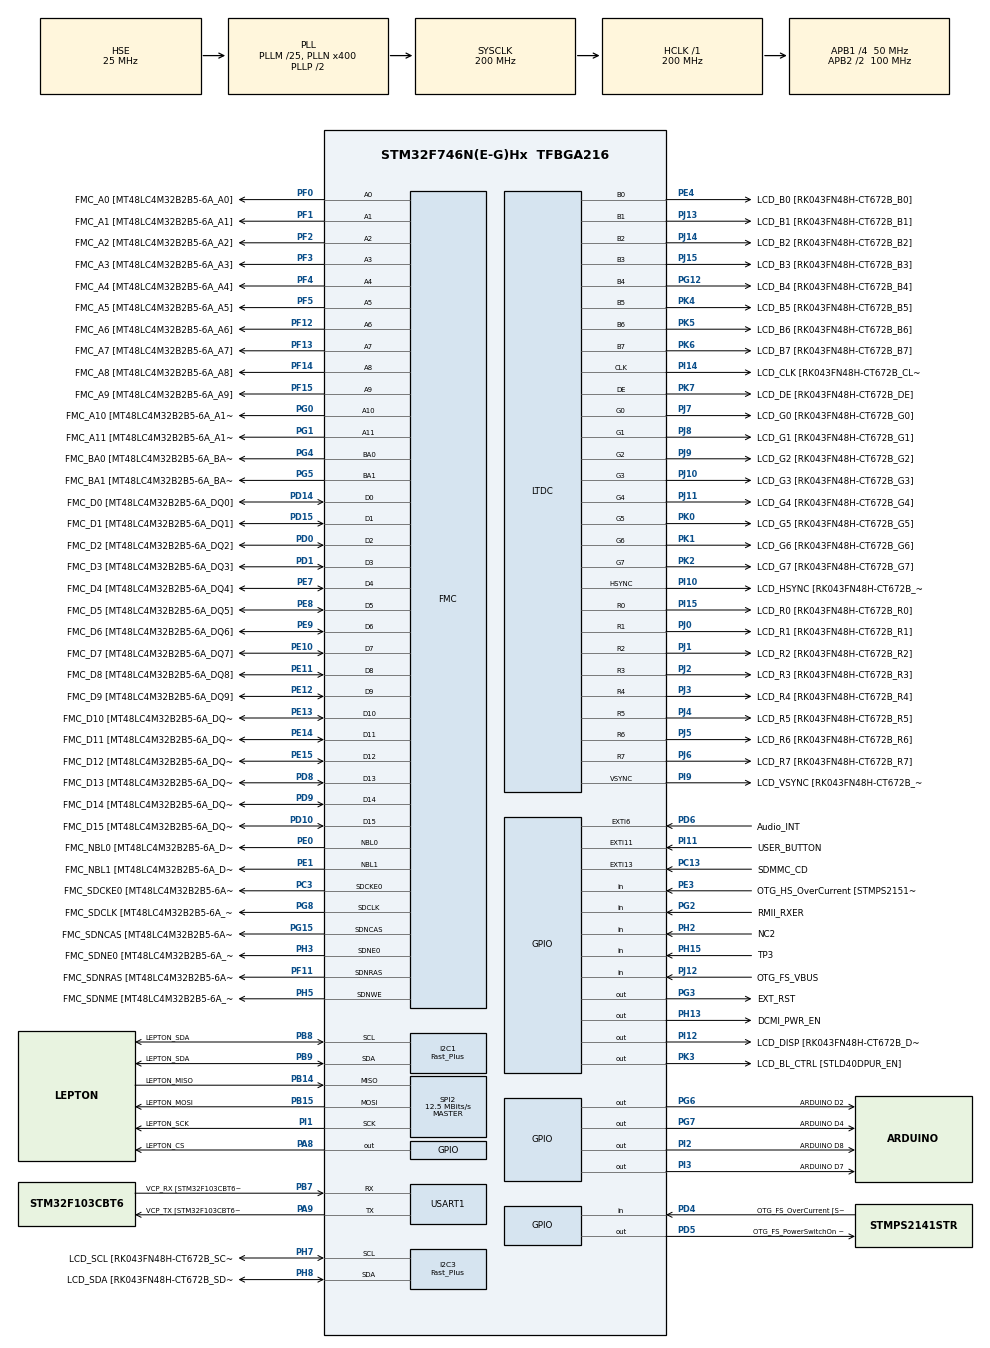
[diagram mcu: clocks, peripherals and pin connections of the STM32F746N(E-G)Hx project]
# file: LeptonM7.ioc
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CORTEX_M7.CPU_DCache=Enabled
CORTEX_M7.CPU_ICache=Enabled
CRC.InputDataFormat=CRC_INPUTDATA_FORMAT_HALFWORDS
DMA2D.AlphaModeForeground=DMA2D_NO_MODIF_ALPHA
DMA2D.InputAlphaForeground=0xFF
Dma.Request0=SPI2_RX
Dma.Request1=SPI2_TX
Dma.SPI2_RX.0.Channel=DMA_CHANNEL_0
Dma.SPI2_RX.0.Direction=DMA_PERIPH_TO_MEMORY
Dma.SPI2_RX.0.FIFOMode=DMA_FIFOMODE_ENABLE
Dma.SPI2_RX.0.FIFOThreshold=DMA_FIFO_THRESHOLD_FULL
Dma.SPI2_RX.0.Instance=DMA1_Stream3
Dma.SPI2_RX.0.MemBurst=DMA_MBURST_SINGLE
Dma.SPI2_RX.0.MemDataAlignment=DMA_MDATAALIGN_BYTE
Dma.SPI2_RX.0.MemInc=DMA_MINC_ENABLE
Dma.SPI2_RX.0.Mode=DMA_NORMAL
Dma.SPI2_RX.0.PeriphBurst=DMA_PBURST_SINGLE
Dma.SPI2_RX.0.PeriphDataAlignment=DMA_PDATAALIGN_BYTE
Dma.SPI2_RX.0.PeriphInc=DMA_PINC_DISABLE
Dma.SPI2_RX.0.Priority=DMA_PRIORITY_VERY_HIGH
Dma.SPI2_TX.1.Channel=DMA_CHANNEL_0
Dma.SPI2_TX.1.Direction=DMA_MEMORY_TO_PERIPH
Dma.SPI2_TX.1.FIFOMode=DMA_FIFOMODE_ENABLE
Dma.SPI2_TX.1.FIFOThreshold=DMA_FIFO_THRESHOLD_FULL
Dma.SPI2_TX.1.Instance=DMA1_Stream4
Dma.SPI2_TX.1.MemBurst=DMA_MBURST_SINGLE
Dma.SPI2_TX.1.MemDataAlignment=DMA_MDATAALIGN_BYTE
Dma.SPI2_TX.1.MemInc=DMA_MINC_ENABLE
Dma.SPI2_TX.1.Mode=DMA_NORMAL
Dma.SPI2_TX.1.PeriphBurst=DMA_PBURST_SINGLE
Dma.SPI2_TX.1.PeriphDataAlignment=DMA_PDATAALIGN_BYTE
Dma.SPI2_TX.1.PeriphInc=DMA_PINC_DISABLE
Dma.SPI2_TX.1.Priority=DMA_PRIORITY_LOW
FMC.CASLatency1=FMC_SDRAM_CAS_LATENCY_2
FMC.ExitSelfRefreshDelay1=6
FMC.LoadToActiveDelay1=2
FMC.RCDDelay1=2
FMC.RPDelay1=2
FMC.RPDelay2=2
FMC.ReadBurst1=FMC_SDRAM_RBURST_ENABLE
FMC.ReadBurst2=FMC_SDRAM_RBURST_ENABLE
FMC.RowBitsNumber1=FMC_SDRAM_ROW_BITS_NUM_12
FMC.RowCycleDelay1=6
FMC.RowCycleDelay2=6
FMC.SDClockPeriod1=FMC_SDRAM_CLOCK_PERIOD_2
FMC.SDClockPeriod2=FMC_SDRAM_CLOCK_PERIOD_2
FMC.SelfRefreshTime1=4
FMC.WriteRecoveryTime1=2
I2C1.I2C_Speed_Mode=I2C_Fast_Plus
I2C1.Speed=400
I2C1.Timing=0x00200A6D
I2C3.I2C_Speed_Mode=I2C_Fast_Plus
I2C3.Speed=400
I2C3.Timing=0x00200A6D
LTDC.ActiveH=272
LTDC.ActiveW=480
LTDC.Alpha_L0=255
LTDC.Alpha_L1=255
LTDC.BlendingFactor1_L0=LTDC_BLENDING_FACTOR1_PAxCA
LTDC.BlendingFactor1_L1=LTDC_BLENDING_FACTOR1_PAxCA
LTDC.BlendingFactor2_L0=LTDC_BLENDING_FACTOR2_PAxCA
LTDC.BlendingFactor2_L1=LTDC_BLENDING_FACTOR2_PAxCA
LTDC.FBStartAdress_L0=0xC0000000
LTDC.FBStartAdress_L1=0xC0100000
LTDC.HBP=13
LTDC.HFP=32
LTDC.HSync=41
LTDC.ImageHeight_L0=240
LTDC.ImageHeight_L1=272
LTDC.ImageWidth_L0=320
LTDC.ImageWidth_L1=480
LTDC.PCPolarity=LTDC_PCPOLARITY_IPC
LTDC.VBP=2
LTDC.VSync=10
LTDC.WindowX0_L0=80
LTDC.WindowX0_L1=0
LTDC.WindowX1_L0=399
LTDC.WindowX1_L1=479
LTDC.WindowY0_L0=16
LTDC.WindowY0_L1=0
LTDC.WindowY1_L0=255
LTDC.WindowY1_L1=271
Mcu.Family=STM32F7
Mcu.Name=STM32F746N(E-G)Hx
Mcu.Package=TFBGA216
NVIC.DMA1_Stream3_IRQn=true\:4\:0\:true
NVIC.DMA1_Stream4_IRQn=true\:3\:0\:true
NVIC.EXTI15_10_IRQn=true\:1\:0\:true
NVIC.PriorityGroup=NVIC_PRIORITYGROUP_4
NVIC.TIM2_IRQn=true\:2\:0\:true
PA0/WKUP.GPIO_Label=ARDUINO A0
PA0/WKUP.GPIO_Mode=GPIO_MODE_ANALOG
PA0/WKUP.GPIO_PuPd=GPIO_NOPULL
PA0/WKUP.Signal=ADCx_IN0
PA1.GPIO_Label=RMII_REF_CLK [LAN8742A-CZ-TR_REFCLK0]
PA1.GPIO_Mode=GPIO_MODE_AF_PP
PA1.GPIO_PuPd=GPIO_NOPULL
PA1.GPIO_Speed=GPIO_SPEED_HIGH
PA1.Signal=ETH_REF_CLK
PA10.GPIO_Label=OTG_FS_ID
PA10.GPIO_Mode=GPIO_MODE_AF_PP
PA10.GPIO_PuPd=GPIO_NOPULL
PA10.GPIO_Speed=GPIO_SPEED_HIGH
PA10.Signal=USB_OTG_FS_ID
PA11.GPIO_Label=OTG_FS_N
PA11.GPIO_Mode=GPIO_MODE_AF_PP
PA11.GPIO_PuPd=GPIO_NOPULL
PA11.GPIO_Speed=GPIO_SPEED_HIGH
PA11.Signal=USB_OTG_FS_DM
PA12.GPIO_Label=OTG_FS_P
PA12.GPIO_Mode=GPIO_MODE_AF_PP
PA12.GPIO_PuPd=GPIO_NOPULL
PA12.GPIO_Speed=GPIO_SPEED_HIGH
PA12.Signal=USB_OTG_FS_DP
PA13.GPIO_Label=SWDIO
PA13.Mode=Trace-Asynchronous_SW
PA13.Signal=SYS_JTMS-SWDIO
PA14.GPIO_Label=SWCLK
PA14.Mode=Trace-Asynchronous_SW
PA14.Signal=SYS_JTCK-SWCLK
PA15.GPIO_Label=ARDUINO PWM/D9
PA15.GPIO_ModeDefaultPP=GPIO_MODE_AF_PP
PA15.GPIO_PuPd=GPIO_NOPULL
PA15.GPIO_Speed=GPIO_SPEED_LOW
PA15.Signal=S_TIM2_CH1_ETR
PA2.GPIO_Label=RMII_MDIO [LAN8742A-CZ-TR_MDIO]
PA2.GPIO_Mode=GPIO_MODE_AF_PP
PA2.GPIO_PuPd=GPIO_NOPULL
PA2.GPIO_Speed=GPIO_SPEED_HIGH
PA2.Signal=ETH_MDIO
PA3.GPIO_Label=ULPI_D0 [USB3320C-EZK_D0]
PA3.GPIO_Mode=GPIO_MODE_AF_PP
PA3.GPIO_PuPd=GPIO_NOPULL
PA3.GPIO_Speed=GPIO_SPEED_HIGH
PA3.Signal=USB_OTG_HS_ULPI_D0
PA4.GPIO_Label=DCMI_HSYNC
PA4.GPIO_Mode=GPIO_MODE_AF_PP
PA4.GPIO_PuPd=GPIO_NOPULL
PA4.GPIO_Speed=GPIO_SPEED_LOW
PA4.Signal=DCMI_HSYNC
PA5.GPIO_Label=ULPI_CLK [USB3320C-EZK_CLKOUT]
PA5.GPIO_Mode=GPIO_MODE_AF_PP
PA5.GPIO_PuPd=GPIO_NOPULL
PA5.GPIO_Speed=GPIO_SPEED_HIGH
PA5.Signal=USB_OTG_HS_ULPI_CK
PA6.Signal=DCMI_PIXCLK
PA7.GPIO_Label=RMII_CRS_DV [LAN8742A-CZ-TR_CRS_DV]
PA7.GPIO_Mode=GPIO_MODE_AF_PP
PA7.GPIO_PuPd=GPIO_NOPULL
PA7.GPIO_Speed=GPIO_SPEED_HIGH
PA7.Signal=ETH_CRS_DV
PA8.GPIO_Label=LEPTON_CS
PA8.GPIO_ModeDefaultOutputPP=GPIO_MODE_OUTPUT_PP
PA8.GPIO_PuPd=GPIO_NOPULL
PA8.GPIO_Speed=GPIO_SPEED_MEDIUM
PA8.Signal=GPIO_Output
PA9.GPIO_Label=VCP_TX [STM32F103CBT6_PA3]
PA9.GPIO_Mode=GPIO_MODE_AF_PP
PA9.GPIO_PuPd=GPIO_NOPULL
PA9.GPIO_Speed=GPIO_SPEED_MEDIUM
PA9.Mode=Asynchronous
PA9.Signal=USART1_TX
PB0.GPIO_Label=ULPI_D1 [USB3320C-EZK_D1]
PB0.GPIO_Mode=GPIO_MODE_AF_PP
PB0.GPIO_PuPd=GPIO_NOPULL
PB0.GPIO_Speed=GPIO_SPEED_HIGH
PB0.Signal=USB_OTG_HS_ULPI_D1
PB1.GPIO_Label=ULPI_D2 [USB3320C-EZK_D2]
PB1.GPIO_Mode=GPIO_MODE_AF_PP
PB1.GPIO_PuPd=GPIO_NOPULL
PB1.GPIO_Speed=GPIO_SPEED_HIGH
PB1.Signal=USB_OTG_HS_ULPI_D2
PB10.GPIO_Label=ULPI_D3 [USB3320C-EZK_D3]
PB10.GPIO_Mode=GPIO_MODE_AF_PP
PB10.GPIO_PuPd=GPIO_NOPULL
PB10.GPIO_Speed=GPIO_SPEED_HIGH
PB10.Signal=USB_OTG_HS_ULPI_D3
PB11.GPIO_Label=ULPI_D4 [USB3320C-EZK_D4]
PB11.GPIO_Mode=GPIO_MODE_AF_PP
PB11.GPIO_PuPd=GPIO_NOPULL
PB11.GPIO_Speed=GPIO_SPEED_HIGH
PB11.Signal=USB_OTG_HS_ULPI_D4
PB12.GPIO_Label=ULPI_D5 [USB3320C-EZK_D5]
PB12.GPIO_Mode=GPIO_MODE_AF_PP
PB12.GPIO_PuPd=GPIO_NOPULL
PB12.GPIO_Speed=GPIO_SPEED_HIGH
PB12.Signal=USB_OTG_HS_ULPI_D5
PB13.GPIO_Label=ULPI_D6 [USB3320C-EZK_D6]
PB13.GPIO_Mode=GPIO_MODE_AF_PP
PB13.GPIO_PuPd=GPIO_NOPULL
PB13.GPIO_Speed=GPIO_SPEED_HIGH
PB13.Signal=USB_OTG_HS_ULPI_D6
PB14.GPIO_Label=LEPTON_MISO
PB14.GPIO_Mode=GPIO_MODE_AF_PP
PB14.GPIO_PuPd=GPIO_NOPULL
PB14.GPIO_Speed=GPIO_SPEED_FAST
PB14.Mode=Full_Duplex_Master
PB14.Signal=SPI2_MISO
PB15.GPIO_Label=LEPTON_MOSI
PB15.GPIO_Mode=GPIO_MODE_AF_PP
PB15.GPIO_PuPd=GPIO_NOPULL
PB15.GPIO_Speed=GPIO_SPEED_FAST
PB15.Mode=Full_Duplex_Master
PB15.Signal=SPI2_MOSI
PB2.Signal=QUADSPI_CLK
PB3.GPIO_Label=SWO
PB3.Mode=Trace-Asynchronous_SW
PB3.Signal=SYS_JTDO-SWO
PB4.GPIO_Label=ARDUINO PWM/D3
PB4.GPIO_ModeDefaultPP=GPIO_MODE_AF_PP
PB4.GPIO_PuPd=GPIO_NOPULL
PB4.GPIO_Speed=GPIO_SPEED_LOW
PB4.Signal=S_TIM3_CH1
PB5.GPIO_Label=ULPI_D7 [USB3320C-EZK_D7]
PB5.GPIO_Mode=GPIO_MODE_AF_PP
PB5.GPIO_PuPd=GPIO_NOPULL
PB5.GPIO_Speed=GPIO_SPEED_HIGH
PB5.Signal=USB_OTG_HS_ULPI_D7
PB6.GPIO_Label=QSPI_NCS [N25Q128A13EF840E_S]
PB6.GPIO_Mode=GPIO_MODE_AF_PP
PB6.GPIO_PuPd=GPIO_NOPULL
PB6.GPIO_Speed=GPIO_SPEED_HIGH
PB6.Signal=QUADSPI_BK1_NCS
PB7.GPIO_Label=VCP_RX [STM32F103CBT6_PA2]
PB7.GPIO_Mode=GPIO_MODE_AF_PP
PB7.GPIO_PuPd=GPIO_NOPULL
PB7.GPIO_Speed=GPIO_SPEED_MEDIUM
PB7.Mode=Asynchronous
PB7.Signal=USART1_RX
PB8.GPIO_Label=LEPTON_SDA
PB8.GPIO_Mode=GPIO_MODE_AF_OD
PB8.GPIO_PuPd=GPIO_NOPULL
PB8.GPIO_PuPdOD=GPIO_PULLUP
PB8.GPIO_Speed=GPIO_SPEED_HIGH
PB8.Mode=I2C
PB8.Signal=I2C1_SCL
PB9.GPIO_Label=LEPTON_SDA
PB9.GPIO_Mode=GPIO_MODE_AF_OD
PB9.GPIO_PuPd=GPIO_NOPULL
PB9.GPIO_PuPdOD=GPIO_PULLUP
PB9.GPIO_Speed=GPIO_SPEED_HIGH
PB9.Mode=I2C
PB9.Signal=I2C1_SDA
PC0.GPIO_Label=ULPI_STP [USB3320C-EZK_STP]
PC0.GPIO_Mode=GPIO_MODE_AF_PP
PC0.GPIO_PuPd=GPIO_NOPULL
PC0.GPIO_Speed=GPIO_SPEED_HIGH
PC0.Signal=USB_OTG_HS_ULPI_STP
PC1.GPIO_Label=RMII_MDC [LAN8742A-CZ-TR_MDC]
PC1.GPIO_Mode=GPIO_MODE_AF_PP
PC1.GPIO_PuPd=GPIO_NOPULL
PC1.GPIO_Speed=GPIO_SPEED_HIGH
PC1.Signal=ETH_MDC
PC10.GPIO_Label=SDMMC_D2
PC10.GPIO_Mode=GPIO_MODE_AF_PP
PC10.GPIO_PuPd=GPIO_NOPULL
PC10.GPIO_Speed_High_Default=GPIO_SPEED_HIGH
PC10.Signal=SDMMC1_D2
PC11.GPIO_Label=SDMMC_D3
PC11.GPIO_Mode=GPIO_MODE_AF_PP
PC11.GPIO_PuPd=GPIO_NOPULL
PC11.GPIO_Speed_High_Default=GPIO_SPEED_HIGH
PC11.Signal=SDMMC1_D3
PC12.GPIO_Label=SDMMC_CK
PC12.GPIO_Mode=GPIO_MODE_AF_PP
PC12.GPIO_PuPd=GPIO_NOPULL
PC12.GPIO_Speed_High_Default=GPIO_SPEED_HIGH
PC12.Signal=SDMMC1_CK
PC13.GPIO_Label=SDMMC_CD
PC13.GPIO_ModeDefaultEXTI=GPIO_MODE_EVT_RISING
PC13.GPIO_PuPd=GPIO_NOPULL
PC13.Signal=GPXTI13
PC14/OSC32_IN.GPIO_Label=RCC_OSC32_IN
PC14/OSC32_IN.Signal=RCC_OSC32_IN
PC15/OSC32_OUT.GPIO_Label=RCC_OSC32_OUT
PC15/OSC32_OUT.Signal=RCC_OSC32_OUT
PC2.GPIO_Label=ULPI_DIR [USB3320C-EZK_DIR]
PC2.GPIO_Mode=GPIO_MODE_AF_PP
PC2.GPIO_PuPd=GPIO_NOPULL
PC2.GPIO_Speed=GPIO_SPEED_HIGH
PC2.Signal=USB_OTG_HS_ULPI_DIR
PC3.GPIO_Label=FMC_SDCKE0 [MT48LC4M32B2B5-6A_CKE]
PC3.GPIO_Mode=GPIO_MODE_AF_PP
PC3.GPIO_PuPd=GPIO_NOPULL
PC3.GPIO_Speed_High_Default=GPIO_SPEED_HIGH
PC3.Mode=SdramChipSelect1_1
PC3.Signal=FMC_SDCKE0
PC4.GPIO_Label=RMII_RXD0 [LAN8742A-CZ-TR_RXD0]
PC4.GPIO_Mode=GPIO_MODE_AF_PP
PC4.GPIO_PuPd=GPIO_NOPULL
PC4.GPIO_Speed=GPIO_SPEED_HIGH
PC4.Signal=ETH_RXD0
PC5.GPIO_Label=RMII_RXD1 [LAN8742A-CZ-TR_RXD1]
PC5.GPIO_Mode=GPIO_MODE_AF_PP
PC5.GPIO_PuPd=GPIO_NOPULL
PC5.GPIO_Speed=GPIO_SPEED_HIGH
PC5.Signal=ETH_RXD1
PC6.GPIO_Label=ARDUINO TX/D1
PC6.GPIO_Mode=GPIO_MODE_AF_PP
PC6.GPIO_PuPd=GPIO_NOPULL
PC6.GPIO_Speed=GPIO_SPEED_HIGH
PC6.Signal=USART6_TX
PC7.GPIO_Label=ARDUINO RX/D0
PC7.GPIO_Mode=GPIO_MODE_AF_PP
PC7.GPIO_PuPd=GPIO_NOPULL
PC7.GPIO_Speed=GPIO_SPEED_HIGH
PC7.Signal=USART6_RX
PC8.GPIO_Label=SDMMC_D0
PC8.GPIO_Mode=GPIO_MODE_AF_PP
PC8.GPIO_PuPd=GPIO_NOPULL
PC8.GPIO_Speed_High_Default=GPIO_SPEED_HIGH
PC8.Signal=SDMMC1_D0
PC9.GPIO_Label=SDMMC_D1
PC9.GPIO_Mode=GPIO_MODE_AF_PP
PC9.GPIO_PuPd=GPIO_NOPULL
PC9.GPIO_Speed_High_Default=GPIO_SPEED_HIGH
PC9.Signal=SDMMC1_D1
PD0.GPIO_Label=FMC_D2 [MT48LC4M32B2B5-6A_DQ2]
PD0.GPIO_Mode=GPIO_MODE_AF_PP
PD0.GPIO_PuPd=GPIO_NOPULL
PD0.GPIO_Speed_High_Default=GPIO_SPEED_HIGH
PD0.Signal=FMC_D2_DA2
PD1.GPIO_Label=FMC_D3 [MT48LC4M32B2B5-6A_DQ3]
PD1.GPIO_Mode=GPIO_MODE_AF_PP
PD1.GPIO_PuPd=GPIO_NOPULL
PD1.GPIO_Speed_High_Default=GPIO_SPEED_HIGH
PD1.Signal=FMC_D3_DA3
PD10.GPIO_Label=FMC_D15 [MT48LC4M32B2B5-6A_DQ15]
PD10.GPIO_Mode=GPIO_MODE_AF_PP
PD10.GPIO_PuPd=GPIO_NOPULL
PD10.GPIO_Speed_High_Default=GPIO_SPEED_HIGH
PD10.Signal=FMC_D15_DA15
PD11.GPIO_Label=QSPI_D0 [N25Q128A13EF840E_DQ0]
PD11.GPIO_Mode=GPIO_MODE_AF_PP
PD11.GPIO_PuPd=GPIO_NOPULL
PD11.GPIO_Speed=GPIO_SPEED_HIGH
PD11.Signal=QUADSPI_BK1_IO0
PD12.GPIO_Label=QSPI_D1 [N25Q128A13EF840E_DQ1]
PD12.GPIO_Mode=GPIO_MODE_AF_PP
PD12.GPIO_PuPd=GPIO_NOPULL
PD12.GPIO_Speed=GPIO_SPEED_HIGH
PD12.Signal=QUADSPI_BK1_IO1
PD13.GPIO_Label=QSPI_D3 [N25Q128A13EF840E_DQ3]
PD13.GPIO_Mode=GPIO_MODE_AF_PP
PD13.GPIO_PuPd=GPIO_NOPULL
PD13.GPIO_Speed=GPIO_SPEED_HIGH
PD13.Signal=QUADSPI_BK1_IO3
PD14.GPIO_Label=FMC_D0 [MT48LC4M32B2B5-6A_DQ0]
PD14.GPIO_Mode=GPIO_MODE_AF_PP
PD14.GPIO_PuPd=GPIO_NOPULL
PD14.GPIO_Speed_High_Default=GPIO_SPEED_HIGH
PD14.Signal=FMC_D0_DA0
PD15.GPIO_Label=FMC_D1 [MT48LC4M32B2B5-6A_DQ1]
PD15.GPIO_Mode=GPIO_MODE_AF_PP
PD15.GPIO_PuPd=GPIO_NOPULL
PD15.GPIO_Speed_High_Default=GPIO_SPEED_HIGH
PD15.Signal=FMC_D1_DA1
PD2.GPIO_Label=SDMMC_D0
PD2.GPIO_Mode=GPIO_MODE_AF_PP
PD2.GPIO_PuPd=GPIO_NOPULL
PD2.GPIO_Speed_High_Default=GPIO_SPEED_HIGH
PD2.Signal=SDMMC1_CMD
PD3.GPIO_Label=DCMI_D5
PD3.GPIO_Mode=GPIO_MODE_AF_PP
PD3.GPIO_PuPd=GPIO_NOPULL
PD3.GPIO_Speed=GPIO_SPEED_LOW
PD3.Signal=DCMI_D5
PD4.GPIO_Label=OTG_FS_OverCurrent [STMPS2141STR_Fault]
PD4.GPIO_Mode=GPIO_MODE_INPUT
PD4.GPIO_PuPd=GPIO_NOPULL
PD4.Signal=GPIO_Input
PD5.GPIO_Label=OTG_FS_PowerSwitchOn [STMPS2141STR_EN]
PD5.GPIO_ModeDefaultOutputPP=GPIO_MODE_OUTPUT_PP
PD5.GPIO_PuPd=GPIO_NOPULL
PD5.GPIO_Speed=GPIO_SPEED_LOW
PD5.Signal=GPIO_Output
PD6.GPIO_Label=Audio_INT
PD6.GPIO_ModeDefaultEXTI=GPIO_MODE_EVT_RISING
PD6.GPIO_PuPd=GPIO_NOPULL
PD6.Signal=GPXTI6
PD7.GPIO_Label=SPDIF_RX0 [74LVC1G04SE_4]
PD7.GPIO_Mode=GPIO_MODE_AF_PP
PD7.GPIO_PuPd=GPIO_NOPULL
PD7.GPIO_Speed=GPIO_SPEED_LOW
PD7.Signal=SPDIFRX_IN0
PD8.GPIO_Label=FMC_D13 [MT48LC4M32B2B5-6A_DQ13]
PD8.GPIO_Mode=GPIO_MODE_AF_PP
PD8.GPIO_PuPd=GPIO_NOPULL
PD8.GPIO_Speed_High_Default=GPIO_SPEED_HIGH
PD8.Signal=FMC_D13_DA13
PD9.GPIO_Label=FMC_D14 [MT48LC4M32B2B5-6A_DQ14]
PD9.GPIO_Mode=GPIO_MODE_AF_PP
PD9.GPIO_PuPd=GPIO_NOPULL
PD9.GPIO_Speed_High_Default=GPIO_SPEED_HIGH
PD9.Signal=FMC_D14_DA14
PE0.GPIO_Label=FMC_NBL0 [MT48LC4M32B2B5-6A_DQM0]
PE0.GPIO_Mode=GPIO_MODE_AF_PP
PE0.GPIO_PuPd=GPIO_NOPULL
PE0.GPIO_Speed_High_Default=GPIO_SPEED_HIGH
PE0.Signal=FMC_NBL0
PE1.GPIO_Label=FMC_NBL1 [MT48LC4M32B2B5-6A_DQM1]
PE1.GPIO_Mode=GPIO_MODE_AF_PP
PE1.GPIO_PuPd=GPIO_NOPULL
PE1.GPIO_Speed_High_Default=GPIO_SPEED_HIGH
PE1.Signal=FMC_NBL1
PE10.GPIO_Label=FMC_D7 [MT48LC4M32B2B5-6A_DQ7]
PE10.GPIO_Mode=GPIO_MODE_AF_PP
PE10.GPIO_PuPd=GPIO_NOPULL
PE10.GPIO_Speed_High_Default=GPIO_SPEED_HIGH
PE10.Signal=FMC_D7_DA7
PE11.GPIO_Label=FMC_D8 [MT48LC4M32B2B5-6A_DQ8]
PE11.GPIO_Mode=GPIO_MODE_AF_PP
PE11.GPIO_PuPd=GPIO_NOPULL
PE11.GPIO_Speed_High_Default=GPIO_SPEED_HIGH
PE11.Signal=FMC_D8_DA8
PE12.GPIO_Label=FMC_D9 [MT48LC4M32B2B5-6A_DQ9]
PE12.GPIO_Mode=GPIO_MODE_AF_PP
PE12.GPIO_PuPd=GPIO_NOPULL
PE12.GPIO_Speed_High_Default=GPIO_SPEED_HIGH
PE12.Signal=FMC_D9_DA9
PE13.GPIO_Label=FMC_D10 [MT48LC4M32B2B5-6A_DQ10]
PE13.GPIO_Mode=GPIO_MODE_AF_PP
PE13.GPIO_PuPd=GPIO_NOPULL
PE13.GPIO_Speed_High_Default=GPIO_SPEED_HIGH
PE13.Signal=FMC_D10_DA10
PE14.GPIO_Label=FMC_D11 [MT48LC4M32B2B5-6A_DQ11]
PE14.GPIO_Mode=GPIO_MODE_AF_PP
PE14.GPIO_PuPd=GPIO_NOPULL
PE14.GPIO_Speed_High_Default=GPIO_SPEED_HIGH
PE14.Signal=FMC_D11_DA11
PE15.GPIO_Label=FMC_D12 [MT48LC4M32B2B5-6A_DQ12]
PE15.GPIO_Mode=GPIO_MODE_AF_PP
PE15.GPIO_PuPd=GPIO_NOPULL
PE15.GPIO_Speed_High_Default=GPIO_SPEED_HIGH
PE15.Signal=FMC_D12_DA12
PE2.GPIO_Label=QSPI_D2 [N25Q128A13EF840E_DQ2]
PE2.GPIO_Mode=GPIO_MODE_AF_PP
PE2.GPIO_PuPd=GPIO_NOPULL
PE2.GPIO_Speed=GPIO_SPEED_HIGH
PE2.Signal=QUADSPI_BK1_IO2
PE3.GPIO_Label=OTG_HS_OverCurrent [STMPS2151STR_FAULT]
PE3.GPIO_Mode=GPIO_MODE_INPUT
PE3.GPIO_PuPd=GPIO_NOPULL
PE3.Signal=GPIO_Input
PE4.GPIO_Label=LCD_B0 [RK043FN48H-CT672B_B0]
PE4.GPIO_Mode=GPIO_MODE_AF_PP
PE4.GPIO_PuPd=GPIO_NOPULL
PE4.GPIO_Speed=GPIO_SPEED_MEDIUM
PE4.Mode=RGB888
PE4.Signal=LTDC_B0
PE5.GPIO_Label=DCMI_D6
PE5.GPIO_Mode=GPIO_MODE_AF_PP
PE5.GPIO_PuPd=GPIO_NOPULL
PE5.GPIO_Speed=GPIO_SPEED_LOW
PE5.Signal=DCMI_D6
PE6.GPIO_Label=DCMI_D7
PE6.GPIO_Mode=GPIO_MODE_AF_PP
PE6.GPIO_PuPd=GPIO_NOPULL
PE6.GPIO_Speed=GPIO_SPEED_LOW
PE6.Signal=DCMI_D7
PE7.GPIO_Label=FMC_D4 [MT48LC4M32B2B5-6A_DQ4]
PE7.GPIO_Mode=GPIO_MODE_AF_PP
PE7.GPIO_PuPd=GPIO_NOPULL
PE7.GPIO_Speed_High_Default=GPIO_SPEED_HIGH
PE7.Signal=FMC_D4_DA4
PE8.GPIO_Label=FMC_D5 [MT48LC4M32B2B5-6A_DQ5]
PE8.GPIO_Mode=GPIO_MODE_AF_PP
PE8.GPIO_PuPd=GPIO_NOPULL
PE8.GPIO_Speed_High_Default=GPIO_SPEED_HIGH
PE8.Signal=FMC_D5_DA5
PE9.GPIO_Label=FMC_D6 [MT48LC4M32B2B5-6A_DQ6]
PE9.GPIO_Mode=GPIO_MODE_AF_PP
PE9.GPIO_PuPd=GPIO_NOPULL
PE9.GPIO_Speed_High_Default=GPIO_SPEED_HIGH
PE9.Signal=FMC_D6_DA6
PF0.GPIO_Label=FMC_A0 [MT48LC4M32B2B5-6A_A0]
PF0.GPIO_Mode=GPIO_MODE_AF_PP
PF0.GPIO_PuPd=GPIO_NOPULL
PF0.GPIO_Speed_High_Default=GPIO_SPEED_HIGH
PF0.Signal=FMC_A0
PF1.GPIO_Label=FMC_A1 [MT48LC4M32B2B5-6A_A1]
PF1.GPIO_Mode=GPIO_MODE_AF_PP
PF1.GPIO_PuPd=GPIO_NOPULL
PF1.GPIO_Speed_High_Default=GPIO_SPEED_HIGH
PF1.Signal=FMC_A1
PF10.GPIO_Label=ARDUINO A1
PF10.GPIO_Mode=GPIO_MODE_ANALOG
PF10.GPIO_PuPd=GPIO_NOPULL
PF10.Signal=ADC3_IN8
PF11.GPIO_Label=FMC_SDNRAS [MT48LC4M32B2B5-6A_RAS]
PF11.GPIO_Mode=GPIO_MODE_AF_PP
PF11.GPIO_PuPd=GPIO_NOPULL
PF11.GPIO_Speed_High_Default=GPIO_SPEED_HIGH
PF11.Signal=FMC_SDNRAS
PF12.GPIO_Label=FMC_A6 [MT48LC4M32B2B5-6A_A6]
PF12.GPIO_Mode=GPIO_MODE_AF_PP
PF12.GPIO_PuPd=GPIO_NOPULL
PF12.GPIO_Speed_High_Default=GPIO_SPEED_HIGH
PF12.Signal=FMC_A6
PF13.GPIO_Label=FMC_A7 [MT48LC4M32B2B5-6A_A7]
PF13.GPIO_Mode=GPIO_MODE_AF_PP
PF13.GPIO_PuPd=GPIO_NOPULL
PF13.GPIO_Speed_High_Default=GPIO_SPEED_HIGH
PF13.Signal=FMC_A7
PF14.GPIO_Label=FMC_A8 [MT48LC4M32B2B5-6A_A8]
PF14.GPIO_Mode=GPIO_MODE_AF_PP
PF14.GPIO_PuPd=GPIO_NOPULL
PF14.GPIO_Speed_High_Default=GPIO_SPEED_HIGH
PF14.Signal=FMC_A8
PF15.GPIO_Label=FMC_A9 [MT48LC4M32B2B5-6A_A9]
PF15.GPIO_Mode=GPIO_MODE_AF_PP
PF15.GPIO_PuPd=GPIO_NOPULL
PF15.GPIO_Speed_High_Default=GPIO_SPEED_HIGH
PF15.Signal=FMC_A9
PF2.GPIO_Label=FMC_A2 [MT48LC4M32B2B5-6A_A2]
PF2.GPIO_Mode=GPIO_MODE_AF_PP
PF2.GPIO_PuPd=GPIO_NOPULL
PF2.GPIO_Speed_High_Default=GPIO_SPEED_HIGH
PF2.Signal=FMC_A2
PF3.GPIO_Label=FMC_A3 [MT48LC4M32B2B5-6A_A3]
PF3.GPIO_Mode=GPIO_MODE_AF_PP
PF3.GPIO_PuPd=GPIO_NOPULL
PF3.GPIO_Speed_High_Default=GPIO_SPEED_HIGH
PF3.Signal=FMC_A3
PF4.GPIO_Label=FMC_A4 [MT48LC4M32B2B5-6A_A4]
PF4.GPIO_Mode=GPIO_MODE_AF_PP
PF4.GPIO_PuPd=GPIO_NOPULL
PF4.GPIO_Speed_High_Default=GPIO_SPEED_HIGH
PF4.Signal=FMC_A4
PF5.GPIO_Label=FMC_A5 [MT48LC4M32B2B5-6A_A5]
PF5.GPIO_Mode=GPIO_MODE_AF_PP
PF5.GPIO_PuPd=GPIO_NOPULL
PF5.GPIO_Speed_High_Default=GPIO_SPEED_HIGH
PF5.Signal=FMC_A5
PF6.GPIO_Label=ARDUINO A5
PF6.GPIO_Mode=GPIO_MODE_ANALOG
PF6.GPIO_PuPd=GPIO_NOPULL
PF6.Signal=ADC3_IN4
PF7.GPIO_Label=ARDUINO A4
PF7.GPIO_Mode=GPIO_MODE_ANALOG
PF7.GPIO_PuPd=GPIO_NOPULL
PF7.Signal=ADC3_IN5
PF8.GPIO_Label=ARDUINO A3
PF8.GPIO_Mode=GPIO_MODE_ANALOG
PF8.GPIO_PuPd=GPIO_NOPULL
PF8.Signal=ADC3_IN6
PF9.GPIO_Label=ARDUINO A2
PF9.GPIO_Mode=GPIO_MODE_ANALOG
PF9.GPIO_PuPd=GPIO_NOPULL
PF9.Signal=ADC3_IN7
PG0.GPIO_Label=FMC_A10 [MT48LC4M32B2B5-6A_A10]
PG0.GPIO_Mode=GPIO_MODE_AF_PP
PG0.GPIO_PuPd=GPIO_NOPULL
PG0.GPIO_Speed_High_Default=GPIO_SPEED_HIGH
PG0.Signal=FMC_A10
PG1.GPIO_Label=FMC_A11 [MT48LC4M32B2B5-6A_A11]
PG1.GPIO_Mode=GPIO_MODE_AF_PP
PG1.GPIO_PuPd=GPIO_NOPULL
PG1.GPIO_Speed_High_Default=GPIO_SPEED_HIGH
PG1.Signal=FMC_A11
PG10.GPIO_Label=SAI2_SDB [WM8994ECS/R_ADCDAT1]
PG10.GPIO_Mode=GPIO_MODE_AF_PP
PG10.GPIO_PuPd=GPIO_NOPULL
PG10.GPIO_Speed=GPIO_SPEED_LOW
PG10.Signal=SAI2_SD_B
PG11.GPIO_Label=RMII_TX_EN [LAN8742A-CZ-TR_TXEN]
PG11.GPIO_Mode=GPIO_MODE_AF_PP
PG11.GPIO_PuPd=GPIO_NOPULL
PG11.GPIO_Speed=GPIO_SPEED_HIGH
PG11.Signal=ETH_TX_EN
PG12.GPIO_Label=LCD_B4 [RK043FN48H-CT672B_B4]
PG12.GPIO_Mode=GPIO_MODE_AF_PP
PG12.GPIO_PuPd=GPIO_NOPULL
PG12.GPIO_Speed=GPIO_SPEED_MEDIUM
PG12.Mode=RGB888
PG12.Signal=LTDC_B4
PG13.GPIO_Label=RMII_TXD0 [LAN8742A-CZ-TR_TXD0]
PG13.GPIO_Mode=GPIO_MODE_AF_PP
PG13.GPIO_PuPd=GPIO_NOPULL
PG13.GPIO_Speed=GPIO_SPEED_HIGH
PG13.Signal=ETH_TXD0
PG14.GPIO_Label=RMII_TXD1 [LAN8742A-CZ-TR_TXD1]
PG14.GPIO_Mode=GPIO_MODE_AF_PP
PG14.GPIO_PuPd=GPIO_NOPULL
PG14.GPIO_Speed=GPIO_SPEED_HIGH
PG14.Signal=ETH_TXD1
PG15.GPIO_Label=FMC_SDNCAS [MT48LC4M32B2B5-6A_CAS]
PG15.GPIO_Mode=GPIO_MODE_AF_PP
PG15.GPIO_PuPd=GPIO_NOPULL
PG15.GPIO_Speed_High_Default=GPIO_SPEED_HIGH
PG15.Signal=FMC_SDNCAS
PG2.GPIO_Label=RMII_RXER
PG2.GPIO_Mode=GPIO_MODE_INPUT
PG2.GPIO_PuPd=GPIO_NOPULL
PG2.Signal=GPIO_Input
PG3.GPIO_Label=EXT_RST
PG3.GPIO_ModeDefaultOutputPP=GPIO_MODE_OUTPUT_PP
PG3.GPIO_PuPd=GPIO_NOPULL
PG3.GPIO_Speed=GPIO_SPEED_LOW
PG3.Signal=GPIO_Output
PG4.GPIO_Label=FMC_BA0 [MT48LC4M32B2B5-6A_BA0]
PG4.GPIO_Mode=GPIO_MODE_AF_PP
PG4.GPIO_PuPd=GPIO_NOPULL
PG4.GPIO_Speed_High_Default=GPIO_SPEED_HIGH
PG4.Signal=FMC_A14_BA0
PG5.GPIO_Label=FMC_BA1 [MT48LC4M32B2B5-6A_BA1]
PG5.GPIO_Mode=GPIO_MODE_AF_PP
PG5.GPIO_PuPd=GPIO_NOPULL
PG5.GPIO_Speed_High_Default=GPIO_SPEED_HIGH
PG5.Signal=FMC_A15_BA1
PG6.GPIO_Label=ARDUINO D2
PG6.GPIO_ModeDefaultOutputPP=GPIO_MODE_OUTPUT_PP
PG6.GPIO_PuPd=GPIO_NOPULL
PG6.GPIO_Speed=GPIO_SPEED_LOW
PG6.Signal=GPIO_Output
PG7.GPIO_Label=ARDUINO D4
PG7.GPIO_ModeDefaultOutputPP=GPIO_MODE_OUTPUT_PP
PG7.GPIO_PuPd=GPIO_NOPULL
PG7.GPIO_Speed=GPIO_SPEED_LOW
PG7.Signal=GPIO_Output
PG8.GPIO_Label=FMC_SDCLK [MT48LC4M32B2B5-6A_CLK]
PG8.GPIO_Mode=GPIO_MODE_AF_PP
PG8.GPIO_PuPd=GPIO_NOPULL
PG8.GPIO_Speed_High_Default=GPIO_SPEED_HIGH
PG8.Signal=FMC_SDCLK
PG9.GPIO_Label=DCMI_VSYNC
PG9.GPIO_Mode=GPIO_MODE_AF_PP
PG9.GPIO_PuPd=GPIO_NOPULL
PG9.GPIO_Speed=GPIO_SPEED_LOW
PG9.Signal=DCMI_VSYNC
PH0/OSC_IN.GPIO_Label=OSC_25M [NZ2520SB-25.00M_OUT]
PH0/OSC_IN.Mode=HSE-External-Clock-Source
PH0/OSC_IN.Signal=RCC_OSC_IN
PH1/OSC_OUT.Mode=HSE-External-Clock-Source
PH1/OSC_OUT.Signal=RCC_OSC_OUT
PH10.GPIO_Label=DCMI_D1
PH10.GPIO_Mode=GPIO_MODE_AF_PP
PH10.GPIO_PuPd=GPIO_NOPULL
PH10.GPIO_Speed=GPIO_SPEED_LOW
PH10.Signal=DCMI_D1
PH11.GPIO_Label=DCMI_D2
PH11.GPIO_Mode=GPIO_MODE_AF_PP
PH11.GPIO_PuPd=GPIO_NOPULL
PH11.GPIO_Speed=GPIO_SPEED_LOW
PH11.Signal=DCMI_D2
PH12.GPIO_Label=DCMI_D3
PH12.GPIO_Mode=GPIO_MODE_AF_PP
PH12.GPIO_PuPd=GPIO_NOPULL
PH12.GPIO_Speed=GPIO_SPEED_LOW
PH12.Signal=DCMI_D3
PH13.GPIO_Label=DCMI_PWR_EN
PH13.GPIO_ModeDefaultOutputPP=GPIO_MODE_OUTPUT_PP
PH13.GPIO_PuPd=GPIO_NOPULL
PH13.GPIO_Speed=GPIO_SPEED_LOW
PH13.Signal=GPIO_Output
PH14.GPIO_Label=DCMI_D4
PH14.GPIO_Mode=GPIO_MODE_AF_PP
PH14.GPIO_PuPd=GPIO_NOPULL
PH14.GPIO_Speed=GPIO_SPEED_LOW
PH14.Signal=DCMI_D4
PH15.GPIO_Label=TP3
PH15.GPIO_Mode=GPIO_MODE_INPUT
PH15.GPIO_PuPd=GPIO_NOPULL
PH15.Signal=GPIO_Input
PH2.GPIO_Label=NC2
PH2.GPIO_Mode=GPIO_MODE_INPUT
PH2.GPIO_PuPd=GPIO_NOPULL
PH2.Signal=GPIO_Input
PH3.GPIO_Label=FMC_SDNE0 [MT48LC4M32B2B5-6A_CS]
PH3.GPIO_Mode=GPIO_MODE_AF_PP
PH3.GPIO_PuPd=GPIO_NOPULL
PH3.GPIO_Speed_High_Default=GPIO_SPEED_HIGH
PH3.Mode=SdramChipSelect1_1
PH3.Signal=FMC_SDNE0
PH4.GPIO_Label=ULPI_NXT [USB3320C-EZK_NXT]
PH4.GPIO_Mode=GPIO_MODE_AF_PP
PH4.GPIO_PuPd=GPIO_NOPULL
PH4.GPIO_Speed=GPIO_SPEED_HIGH
PH4.Signal=USB_OTG_HS_ULPI_NXT
PH5.GPIO_Label=FMC_SDNME [MT48LC4M32B2B5-6A_WE]
PH5.GPIO_Mode=GPIO_MODE_AF_PP
PH5.GPIO_PuPd=GPIO_NOPULL
PH5.GPIO_Speed_High_Default=GPIO_SPEED_HIGH
PH5.Signal=FMC_SDNWE
PH6.GPIO_Label=ARDUINO PWM/D6
PH6.GPIO_ModeDefaultPP=GPIO_MODE_AF_PP
PH6.GPIO_PuPd=GPIO_NOPULL
PH6.GPIO_Speed=GPIO_SPEED_LOW
PH6.Signal=S_TIM12_CH1
PH7.GPIO_Label=LCD_SCL [RK043FN48H-CT672B_SCL]
PH7.GPIO_Mode=GPIO_MODE_AF_OD
PH7.GPIO_PuPdOD=GPIO_PULLUP
PH7.GPIO_Speed=GPIO_SPEED_HIGH
PH7.Mode=I2C
PH7.Signal=I2C3_SCL
PH8.GPIO_Label=LCD_SDA [RK043FN48H-CT672B_SDA]
PH8.GPIO_Mode=GPIO_MODE_AF_OD
PH8.GPIO_PuPdOD=GPIO_PULLUP
PH8.GPIO_Speed=GPIO_SPEED_HIGH
PH8.Mode=I2C
PH8.Signal=I2C3_SDA
PH9.GPIO_Label=DCMI_D0
PH9.GPIO_Mode=GPIO_MODE_AF_PP
PH9.GPIO_PuPd=GPIO_NOPULL
PH9.GPIO_Speed=GPIO_SPEED_LOW
PH9.Signal=DCMI_D0
PI0.GPIO_Label=ARDUINO PWM/CS/D10
PI0.GPIO_ModeDefaultPP=GPIO_MODE_AF_PP
PI0.GPIO_PuPd=GPIO_NOPULL
PI0.GPIO_Speed=GPIO_SPEED_LOW
PI0.Signal=S_TIM5_CH4
PI1.GPIO_Label=LEPTON_SCK
PI1.GPIO_Mode=GPIO_MODE_AF_PP
PI1.GPIO_PuPd=GPIO_NOPULL
PI1.GPIO_Speed=GPIO_SPEED_FAST
PI1.Mode=Full_Duplex_Master
PI1.Signal=SPI2_SCK
PI10.GPIO_Label=LCD_HSYNC [RK043FN48H-CT672B_HSYNC]
PI10.GPIO_Mode=GPIO_MODE_AF_PP
PI10.GPIO_PuPd=GPIO_NOPULL
PI10.GPIO_Speed=GPIO_SPEED_MEDIUM
PI10.Mode=RGB888
PI10.Signal=LTDC_HSYNC
PI11.GPIO_Label=USER_BUTTON
PI11.GPIO_ModeDefaultEXTI=GPIO_MODE_IT_RISING
PI11.GPIO_PuPd=GPIO_NOPULL
PI11.Signal=GPXTI11
PI12.GPIO_Label=LCD_DISP [RK043FN48H-CT672B_DISP] 
PI12.GPIO_ModeDefaultOutputPP=GPIO_MODE_OUTPUT_PP
PI12.GPIO_PuPd=GPIO_NOPULL
PI12.GPIO_Speed=GPIO_SPEED_LOW
PI12.Signal=GPIO_Output
PI14.GPIO_Label=LCD_CLK [RK043FN48H-CT672B_CLK]
PI14.GPIO_Mode=GPIO_MODE_AF_PP
PI14.GPIO_PuPd=GPIO_NOPULL
PI14.GPIO_Speed=GPIO_SPEED_MEDIUM
PI14.Mode=RGB888
PI14.Signal=LTDC_CLK
PI15.GPIO_Label=LCD_R0 [RK043FN48H-CT672B_R0]
PI15.GPIO_Mode=GPIO_MODE_AF_PP
PI15.GPIO_PuPd=GPIO_NOPULL
PI15.GPIO_Speed=GPIO_SPEED_MEDIUM
PI15.Mode=RGB888
PI15.Signal=LTDC_R0
PI2.GPIO_Label=ARDUINO D8
PI2.GPIO_ModeDefaultOutputPP=GPIO_MODE_OUTPUT_PP
PI2.GPIO_PuPd=GPIO_NOPULL
PI2.GPIO_Speed=GPIO_SPEED_LOW
PI2.Signal=GPIO_Output
PI3.GPIO_Label=ARDUINO D7
PI3.GPIO_ModeDefaultOutputPP=GPIO_MODE_OUTPUT_PP
PI3.GPIO_PuPd=GPIO_NOPULL
PI3.GPIO_Speed=GPIO_SPEED_LOW
PI3.Signal=GPIO_Output
PI4.GPIO_Label=SAI2_MCLKA [WM8994ECS/R_MCLK1]
PI4.GPIO_Mode=GPIO_MODE_AF_PP
PI4.GPIO_PuPd=GPIO_NOPULL
PI4.GPIO_Speed=GPIO_SPEED_LOW
PI4.Signal=SAI2_MCLK_A
PI5.GPIO_Label=SAI2_SCKA [WM8994ECS/R_BCLK1]
PI5.GPIO_Mode=GPIO_MODE_AF_PP
PI5.GPIO_PuPd=GPIO_NOPULL
PI5.GPIO_Speed=GPIO_SPEED_LOW
PI5.Signal=SAI2_SCK_A
PI6.GPIO_Label=SAI2_SDA [WM8994ECS/R_DACDAT1]
PI6.GPIO_Mode=GPIO_MODE_AF_PP
PI6.GPIO_PuPd=GPIO_NOPULL
PI6.GPIO_Speed=GPIO_SPEED_LOW
PI6.Signal=SAI2_SD_A
PI7.GPIO_Label=SAI2_FSA [WM8994ECS/R_LRCLK1]
PI7.GPIO_Mode=GPIO_MODE_AF_PP
PI7.GPIO_PuPd=GPIO_NOPULL
PI7.GPIO_Speed=GPIO_SPEED_LOW
PI7.Signal=SAI2_FS_A
PI8.GPIO_Label=NC1 [TP2]
PI8.Signal=RTC_TS
PI9.GPIO_Label=LCD_VSYNC [RK043FN48H-CT672B_VSYNC]
PI9.GPIO_Mode=GPIO_MODE_AF_PP
PI9.GPIO_PuPd=GPIO_NOPULL
PI9.GPIO_Speed=GPIO_SPEED_MEDIUM
PI9.Mode=RGB888
PI9.Signal=LTDC_VSYNC
PJ0.GPIO_Label=LCD_R1 [RK043FN48H-CT672B_R1]
PJ0.GPIO_Mode=GPIO_MODE_AF_PP
PJ0.GPIO_PuPd=GPIO_NOPULL
PJ0.GPIO_Speed=GPIO_SPEED_MEDIUM
PJ0.Mode=RGB888
PJ0.Signal=LTDC_R1
PJ1.GPIO_Label=LCD_R2 [RK043FN48H-CT672B_R2]
PJ1.GPIO_Mode=GPIO_MODE_AF_PP
PJ1.GPIO_PuPd=GPIO_NOPULL
PJ1.GPIO_Speed=GPIO_SPEED_MEDIUM
PJ1.Mode=RGB888
PJ1.Signal=LTDC_R2
PJ10.GPIO_Label=LCD_G3 [RK043FN48H-CT672B_G3]
PJ10.GPIO_Mode=GPIO_MODE_AF_PP
PJ10.GPIO_PuPd=GPIO_NOPULL
PJ10.GPIO_Speed=GPIO_SPEED_MEDIUM
PJ10.Mode=RGB888
PJ10.Signal=LTDC_G3
PJ11.GPIO_Label=LCD_G4 [RK043FN48H-CT672B_G4]
PJ11.GPIO_Mode=GPIO_MODE_AF_PP
PJ11.GPIO_PuPd=GPIO_NOPULL
PJ11.GPIO_Speed=GPIO_SPEED_MEDIUM
PJ11.Mode=RGB888
PJ11.Signal=LTDC_G4
PJ12.GPIO_Label=OTG_FS_VBUS
PJ12.GPIO_Mode=GPIO_MODE_INPUT
PJ12.GPIO_PuPd=GPIO_NOPULL
PJ12.Signal=GPIO_Input
PJ13.GPIO_Label=LCD_B1 [RK043FN48H-CT672B_B1]
PJ13.GPIO_Mode=GPIO_MODE_AF_PP
PJ13.GPIO_PuPd=GPIO_NOPULL
PJ13.GPIO_Speed=GPIO_SPEED_MEDIUM
PJ13.Mode=RGB888
PJ13.Signal=LTDC_B1
PJ14.GPIO_Label=LCD_B2 [RK043FN48H-CT672B_B2]
PJ14.GPIO_Mode=GPIO_MODE_AF_PP
PJ14.GPIO_PuPd=GPIO_NOPULL
PJ14.GPIO_Speed=GPIO_SPEED_MEDIUM
PJ14.Mode=RGB888
PJ14.Signal=LTDC_B2
PJ15.GPIO_Label=LCD_B3 [RK043FN48H-CT672B_B3]
PJ15.GPIO_Mode=GPIO_MODE_AF_PP
PJ15.GPIO_PuPd=GPIO_NOPULL
PJ15.GPIO_Speed=GPIO_SPEED_MEDIUM
PJ15.Mode=RGB888
PJ15.Signal=LTDC_B3
PJ2.GPIO_Label=LCD_R3 [RK043FN48H-CT672B_R3]
PJ2.GPIO_Mode=GPIO_MODE_AF_PP
PJ2.GPIO_PuPd=GPIO_NOPULL
PJ2.GPIO_Speed=GPIO_SPEED_MEDIUM
PJ2.Mode=RGB888
PJ2.Signal=LTDC_R3
PJ3.GPIO_Label=LCD_R4 [RK043FN48H-CT672B_R4]
PJ3.GPIO_Mode=GPIO_MODE_AF_PP
PJ3.GPIO_PuPd=GPIO_NOPULL
PJ3.GPIO_Speed=GPIO_SPEED_MEDIUM
PJ3.Mode=RGB888
PJ3.Signal=LTDC_R4
PJ4.GPIO_Label=LCD_R5 [RK043FN48H-CT672B_R5]
PJ4.GPIO_Mode=GPIO_MODE_AF_PP
PJ4.GPIO_PuPd=GPIO_NOPULL
PJ4.GPIO_Speed=GPIO_SPEED_MEDIUM
PJ4.Mode=RGB888
PJ4.Signal=LTDC_R5
PJ5.GPIO_Label=LCD_R6 [RK043FN48H-CT672B_R6]
PJ5.GPIO_Mode=GPIO_MODE_AF_PP
PJ5.GPIO_PuPd=GPIO_NOPULL
PJ5.GPIO_Speed=GPIO_SPEED_MEDIUM
PJ5.Mode=RGB888
PJ5.Signal=LTDC_R6
PJ6.GPIO_Label=LCD_R7 [RK043FN48H-CT672B_R7]
PJ6.GPIO_Mode=GPIO_MODE_AF_PP
PJ6.GPIO_PuPd=GPIO_NOPULL
PJ6.GPIO_Speed=GPIO_SPEED_MEDIUM
PJ6.Mode=RGB888
PJ6.Signal=LTDC_R7
PJ7.GPIO_Label=LCD_G0 [RK043FN48H-CT672B_G0]
PJ7.GPIO_Mode=GPIO_MODE_AF_PP
PJ7.GPIO_PuPd=GPIO_NOPULL
PJ7.GPIO_Speed=GPIO_SPEED_MEDIUM
PJ7.Mode=RGB888
PJ7.Signal=LTDC_G0
PJ8.GPIO_Label=LCD_G1 [RK043FN48H-CT672B_G1]
PJ8.GPIO_Mode=GPIO_MODE_AF_PP
PJ8.GPIO_PuPd=GPIO_NOPULL
PJ8.GPIO_Speed=GPIO_SPEED_MEDIUM
PJ8.Mode=RGB888
PJ8.Signal=LTDC_G1
PJ9.GPIO_Label=LCD_G2 [RK043FN48H-CT672B_G2]
PJ9.GPIO_Mode=GPIO_MODE_AF_PP
PJ9.GPIO_PuPd=GPIO_NOPULL
PJ9.GPIO_Speed=GPIO_SPEED_MEDIUM
PJ9.Mode=RGB888
PJ9.Signal=LTDC_G2
PK0.GPIO_Label=LCD_G5 [RK043FN48H-CT672B_G5]
PK0.GPIO_Mode=GPIO_MODE_AF_PP
PK0.GPIO_PuPd=GPIO_NOPULL
PK0.GPIO_Speed=GPIO_SPEED_MEDIUM
PK0.Mode=RGB888
PK0.Signal=LTDC_G5
PK1.GPIO_Label=LCD_G6 [RK043FN48H-CT672B_G6]
PK1.GPIO_Mode=GPIO_MODE_AF_PP
PK1.GPIO_PuPd=GPIO_NOPULL
PK1.GPIO_Speed=GPIO_SPEED_MEDIUM
PK1.Mode=RGB888
PK1.Signal=LTDC_G6
PK2.GPIO_Label=LCD_G7 [RK043FN48H-CT672B_G7]
PK2.GPIO_Mode=GPIO_MODE_AF_PP
PK2.GPIO_PuPd=GPIO_NOPULL
PK2.GPIO_Speed=GPIO_SPEED_MEDIUM
PK2.Mode=RGB888
PK2.Signal=LTDC_G7
PK3.GPIO_Label=LCD_BL_CTRL [STLD40DPUR_EN]
PK3.GPIO_ModeDefaultOutputPP=GPIO_MODE_OUTPUT_PP
PK3.GPIO_PuPd=GPIO_NOPULL
PK3.GPIO_Speed=GPIO_SPEED_HIGH
PK3.Signal=GPIO_Output
PK4.GPIO_Label=LCD_B5 [RK043FN48H-CT672B_B5]
PK4.GPIO_Mode=GPIO_MODE_AF_PP
PK4.GPIO_PuPd=GPIO_NOPULL
PK4.GPIO_Speed=GPIO_SPEED_MEDIUM
PK4.Mode=RGB888
PK4.Signal=LTDC_B5
PK5.GPIO_Label=LCD_B6 [RK043FN48H-CT672B_B6]
PK5.GPIO_Mode=GPIO_MODE_AF_PP
PK5.GPIO_PuPd=GPIO_NOPULL
PK5.GPIO_Speed=GPIO_SPEED_MEDIUM
PK5.Mode=RGB888
PK5.Signal=LTDC_B6
PK6.GPIO_Label=LCD_B7 [RK043FN48H-CT672B_B7]
PK6.GPIO_Mode=GPIO_MODE_AF_PP
PK6.GPIO_PuPd=GPIO_NOPULL
PK6.GPIO_Speed=GPIO_SPEED_MEDIUM
PK6.Mode=RGB888
PK6.Signal=LTDC_B7
PK7.GPIO_Label=LCD_DE [RK043FN48H-CT672B_DE]
PK7.GPIO_Mode=GPIO_MODE_AF_PP
PK7.GPIO_PuPd=GPIO_NOPULL
PK7.GPIO_Speed=GPIO_SPEED_MEDIUM
PK7.Mode=RGB888
PK7.Signal=LTDC_DE
ProjectManager.TargetToolchain=MDK-ARM V5
RCC.AHBFreq_Value=200000000
RCC.APB1CLKDivider=RCC_HCLK_DIV4
RCC.APB1Freq_Value=50000000
RCC.APB1TimFreq_Value=100000000
RCC.APB2CLKDivider=RCC_HCLK_DIV2
RCC.APB2Freq_Value=100000000
RCC.APB2TimFreq_Value=200000000
RCC.CortexFreq_Value=200000000
RCC.EnbaleCSS=true
RCC.HCLKFreq_Value=200000000
RCC.HSE_VALUE=25000000
RCC.HSI_VALUE=16000000
RCC.LSE_VALUE=32768
RCC.PLLM=25
RCC.PLLN=400
RCC.PLLSAIR=5
RCC.PLLSAIRDiv=RCC_PLLSAIDIVR_4
RCC.PLLSourceVirtual=RCC_PLLSOURCE_HSE
RCC.SYSCLKFreq_VALUE=200000000
RCC.SYSCLKSource=RCC_SYSCLKSOURCE_PLLCLK
RCC.USBFreq_Value=200000000
RCC.VCOOutputFreq_Value=400000000
SH.ADCx_IN0.0=ADC3_IN0
SH.FMC_A0.0=FMC_A0,12b-sda1
SH.FMC_A1.0=FMC_A1,12b-sda1
SH.FMC_A10.0=FMC_A10,12b-sda1
SH.FMC_A11.0=FMC_A11,12b-sda1
SH.FMC_A14_BA0.0=FMC_BA0,FourSdramBanks1
SH.FMC_A15_BA1.0=FMC_BA1,FourSdramBanks1
SH.FMC_A2.0=FMC_A2,12b-sda1
SH.FMC_A3.0=FMC_A3,12b-sda1
SH.FMC_A4.0=FMC_A4,12b-sda1
SH.FMC_A5.0=FMC_A5,12b-sda1
SH.FMC_A6.0=FMC_A6,12b-sda1
SH.FMC_A7.0=FMC_A7,12b-sda1
SH.FMC_A8.0=FMC_A8,12b-sda1
SH.FMC_A9.0=FMC_A9,12b-sda1
SH.FMC_D0_DA0.0=FMC_D0,sd-16b-d1
SH.FMC_D10_DA10.0=FMC_D10,sd-16b-d1
SH.FMC_D11_DA11.0=FMC_D11,sd-16b-d1
SH.FMC_D12_DA12.0=FMC_D12,sd-16b-d1
SH.FMC_D13_DA13.0=FMC_D13,sd-16b-d1
SH.FMC_D14_DA14.0=FMC_D14,sd-16b-d1
SH.FMC_D15_DA15.0=FMC_D15,sd-16b-d1
SH.FMC_D1_DA1.0=FMC_D1,sd-16b-d1
SH.FMC_D2_DA2.0=FMC_D2,sd-16b-d1
SH.FMC_D3_DA3.0=FMC_D3,sd-16b-d1
SH.FMC_D4_DA4.0=FMC_D4,sd-16b-d1
SH.FMC_D5_DA5.0=FMC_D5,sd-16b-d1
SH.FMC_D6_DA6.0=FMC_D6,sd-16b-d1
SH.FMC_D7_DA7.0=FMC_D7,sd-16b-d1
SH.FMC_D8_DA8.0=FMC_D8,sd-16b-d1
SH.FMC_D9_DA9.0=FMC_D9,sd-16b-d1
SH.FMC_NBL0.0=FMC_NBL0,Sd2ByteEnable1
SH.FMC_NBL1.0=FMC_NBL1,Sd2ByteEnable1
SH.FMC_SDCLK.0=FMC_SDCLK,12b-sda1
SH.FMC_SDNCAS.0=FMC_SDNCAS,12b-sda1
SH.FMC_SDNRAS.0=FMC_SDNRAS,12b-sda1
SH.FMC_SDNWE.0=FMC_SDNWE,12b-sda1
SH.S_TIM12_CH1.0=TIM12_CH1
SH.S_TIM2_CH1_ETR.0=TIM2_CH1
SH.S_TIM3_CH1.0=TIM3_CH1
SH.S_TIM5_CH4.0=TIM5_CH4
SPI2.BaudRatePrescaler=SPI_BAUDRATEPRESCALER_4
SPI2.CLKPhase=SPI_PHASE_2EDGE
SPI2.CLKPolarity=SPI_POLARITY_HIGH
SPI2.CalculateBaudRate=12.5 MBits/s
SPI2.DataSize=SPI_DATASIZE_8BIT
SPI2.Mode=SPI_MODE_MASTER
TIM2.CounterMode=TIM_COUNTERMODE_DOWN
TIM2.Period=0xFFFFFFFF
TIM2.Prescaler=99
USART1.WordLength=UART_WORDLENGTH_8B
VP_CRC_VS_CRC.Mode=CRC_Activate
VP_DMA2D_VS_DMA2D.Mode=DMA2D_Activate
VP_TIM2_VS_ClockSourceINT.Mode=Internal
VP_TIM2_VS_OPM.Mode=OPM_bit
board=STM32F746G-DISCO

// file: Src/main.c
/**
  ******************************************************************************
  * File Name          : main.c
  * Description        : Main program body
  ******************************************************************************
  *
  * COPYRIGHT(c) 2015 STMicroelectronics
  *
  * Redistribution and use in source and binary forms, with or without modification,
  * are permitted provided that the following conditions are met:
  *   1. Redistributions of source code must retain the above copyright notice,
  *      this list of conditions and the following disclaimer.
  *   2. Redistributions in binary form must reproduce the above copyright notice,
  *      this list of conditions and the following disclaimer in the documentation
  *      and/or other materials provided with the distribution.
  *   3. Neither the name of STMicroelectronics nor the names of its contributors
  *      may be used to endorse or promote products derived from this software
  *      without specific prior written permission.
  *
  * THIS SOFTWARE IS PROVIDED BY THE COPYRIGHT HOLDERS AND CONTRIBUTORS "AS IS"
  * AND ANY EXPRESS OR IMPLIED WARRANTIES, INCLUDING, BUT NOT LIMITED TO, THE
  * IMPLIED WARRANTIES OF MERCHANTABILITY AND FITNESS FOR A PARTICULAR PURPOSE ARE
  * DISCLAIMED. IN NO EVENT SHALL THE COPYRIGHT HOLDER OR CONTRIBUTORS BE LIABLE
  * FOR ANY DIRECT, INDIRECT, INCIDENTAL, SPECIAL, EXEMPLARY, OR CONSEQUENTIAL
  * DAMAGES (INCLUDING, BUT NOT LIMITED TO, PROCUREMENT OF SUBSTITUTE GOODS OR
  * SERVICES; LOSS OF USE, DATA, OR PROFITS; OR BUSINESS INTERRUPTION) HOWEVER
  * CAUSED AND ON ANY THEORY OF LIABILITY, WHETHER IN CONTRACT, STRICT LIABILITY,
  * OR TORT (INCLUDING NEGLIGENCE OR OTHERWISE) ARISING IN ANY WAY OUT OF THE USE
  * OF THIS SOFTWARE, EVEN IF ADVISED OF THE POSSIBILITY OF SUCH DAMAGE.
  *
  ******************************************************************************
  */
#include "stm32f7xx_hal.h"

/* USER CODE BEGIN Includes */
#include "main.h"
/* USER CODE END Includes */

CRC_HandleTypeDef hcrc;

DMA2D_HandleTypeDef hdma2d;

I2C_HandleTypeDef hi2c1;
I2C_HandleTypeDef hi2c3;

LTDC_HandleTypeDef hltdc;

SPI_HandleTypeDef hspi2;
DMA_HandleTypeDef hdma_spi2_rx;
DMA_HandleTypeDef hdma_spi2_tx;

TIM_HandleTypeDef htim2;

UART_HandleTypeDef huart1;

SDRAM_HandleTypeDef hsdram1;

/* USER CODE BEGIN PV */
/* Private variables ---------------------------------------------------------*/
FMC_SDRAM_CommandTypeDef command;

uint32_t * Display_layer0 = (uint32_t *) DISPLAY_LAYER0_ADDR;
uint32_t * Display_layer1 = (uint32_t *) DISPLAY_LAYER1_ADDR;

//uint32_t * Button_Layout = (uint32_t *) 0xC0200000;
/* USER CODE END PV */

void SystemClock_Config(void);
static void MX_GPIO_Init(void);
static void MX_DMA_Init(void);
static void MX_CRC_Init(void);
static void MX_DMA2D_Init(void);
static void MX_FMC_Init(void);
static void MX_I2C1_Init(void);
static void MX_I2C3_Init(void);
static void MX_LTDC_Init(void);
static void MX_SPI2_Init(void);
static void MX_TIM2_Init(void);
static void MX_USART1_UART_Init(void);

/* USER CODE BEGIN PFP */
/* Private function prototypes -----------------------------------------------*/
static void SDRAM_Init(void);
/* USER CODE END PFP */

/* USER CODE BEGIN 0 */
void ArrayMaxMin(uint16_t * LeptonBuffer, uint16_t * min, uint16_t * max);
void GenerateDisplayBuffer(uint8_t LeptonBufferID, uint8_t DisplayBufferID);
uint32_t gradient(float percent);
uint32_t two_colors_gradient(float percent, uint8_t r_1, uint8_t g_1, uint8_t b_1, uint8_t r_2, uint8_t g_2, uint8_t b_2);
//void drawButton(int x, int y);
/* USER CODE END 0 */

int main(void)
{

  /* USER CODE BEGIN 1 */
  int x, y;
  uint16_t dummy = 0x00;
  uint8_t current_buffer = 0, next_buffer = 1;
  uint32_t tmp_color;
  /* USER CODE END 1 */

  /* Enable I-Cache-------------------------------------------------------------*/
  SCB_EnableICache();

  /* Enable D-Cache-------------------------------------------------------------*/
  SCB_EnableDCache();

  /* MCU Configuration----------------------------------------------------------*/

  /* Reset of all peripherals, Initializes the Flash interface and the Systick. */
  HAL_Init();

  /* Configure the system clock */
  SystemClock_Config();

  /* Initialize all configured peripherals */
  MX_GPIO_Init();
  MX_DMA_Init();
  MX_CRC_Init();
  MX_DMA2D_Init();
  MX_FMC_Init();
  SDRAM_Init();
  MX_I2C1_Init();
  MX_I2C3_Init();
  MX_LTDC_Init();
  MX_SPI2_Init();
  MX_TIM2_Init();
  MX_USART1_UART_Init();

  /* USER CODE BEGIN 2 */
  LEPTON_CS_HIGH();
  while(HAL_SPI_Transmit(&hspi2, (uint8_t *)&dummy, 1, 0xFFFFFFFF) != HAL_OK);
//  for(y = 0; y < 240*320; y++)
//      Display_layer0_buffer0[y] = Display_layer0_buffer1[y] = 0;
  for(y = 0; y < 272*480; y++)
      Display_layer0[y] = Display_layer1[y] = 0;
  TFT_LCD_EN();
  TFT_BL_ON();
  for(y = 0; y < 60; y++)
      for(x = 0; x < 80; x++)
          LeptonBuffer[0][y*80 + x] = LeptonBuffer[1][y*80 + x] = 0;
  initTextBuffer(Display_layer0, 480, 272, 0, 0, Arial12x12, 0xFFFFFFFF, 0xFF000000);
  for(x = 0; x < 322; x++)
    Display_layer0[15*480+x+79] = Display_layer0[256*480+x+79] = Display_layer1[15*480+x+79] = Display_layer1[256*480+x+79] = 0xFF7F7F7F;
  for(y = 0; y < 240; y++)
    Display_layer0[(y+16)*480+79] = Display_layer0[(y+16)*480+400] = Display_layer1[(y+16)*480+79] = Display_layer1[(y+16)*480+400] = 0xFF7F7F7F;
  for(y = 0; y < 240; y++)
  {
      tmp_color = gradient(1.0f-y/240.0f);
      for(x = 2; x < 18; x++)
          Display_layer0[(y+16)*480+x] = Display_layer1[(y+16)*480+x] = tmp_color;
      Display_layer0[(y+16)*480+1] = Display_layer1[(y+16)*480+1] = 0xFF7F7F7F;
      Display_layer0[(y+16)*480+18] = Display_layer1[(y+16)*480+18] = 0xFF7F7F7F;
  }
  for(x = 2; x < 21; x++)
  {
      Display_layer0[16*480+x] = Display_layer1[16*480+x] = 0xFFFFFFFF;//White level
      Display_layer0[76*480+x] = Display_layer1[76*480+x] = 0xFFFFFFFF;//Red level
      Display_layer0[136*480+x] = Display_layer1[136*480+x] = 0xFFFFFFFF;//Yellow level
      Display_layer0[196*480+x] = Display_layer1[196*480+x] = 0xFFFFFFFF;//Blue Level
      Display_layer0[255*480+x] = Display_layer1[255*480+x] = 0xFFFFFFFF;//Black level
  }
//  for(y = 0; y < 32; y++)
//  {
//      tmp_color = two_colors_gradient(y/32.0f, 0xDF, 0xDF, 0xDF, 0x9F, 0x9F, 0x9F);
//      for(x = 0; x < 64; x++)
//      {
//          Button_Layout[y*64+x] = tmp_color;
//      }
//  }
  //wait_ms(200);

  LeptonSync();
  LEPTON_CS_LOW();
	wait_ms(190);
	LeptonSync();
  while(HAL_SPI_Receive_DMA(&hspi2, (uint8_t *) Lepton_VoSPI, 164) != HAL_OK);
	LEPTON_CS_LOW();
  //for(x = 0; x < 5; x++)
  //  drawButton(410, 24+48*x);
  /* USER CODE END 2 */

  /* Infinite loop */
  while (1)
  {

  /* USER CODE BEGIN 3 */

    /*HAL_I2C_Mem_Read(&hi2c3, TOUCH_I2C_ADDR, TOUCH_REG_STATUS, 1, &test_var, 1, 0xFFFF);
    printf("\r0x%02X", test_var);

    HAL_I2C_Mem_Read(&hi2c3, TOUCH_I2C_ADDR, TOUCH_REG_T0_WEIGHT, 1, &test_var, 1, 0xFFFF);
    printf(" 0x%02X ", test_var);*/

    if(BufferStatus[0] == BUFFER_RDY_DISP)
    {
        BufferStatus[0] = BUFFER_BUSY_DISP;
        GenerateDisplayBuffer(0, next_buffer);
        if(next_buffer == 0)
				{
					  __HAL_LTDC_LAYER_ENABLE(&hltdc, 0);
					  __HAL_LTDC_LAYER_DISABLE(&hltdc, 1);
            //HAL_LTDC_SetAddress(&hltdc, (uint32_t) Display_layer0_buffer0, 0);
				}
        else
				{
					  __HAL_LTDC_LAYER_ENABLE(&hltdc, 1);
					  __HAL_LTDC_LAYER_DISABLE(&hltdc, 0);
            //HAL_LTDC_SetAddress(&hltdc, (uint32_t) Display_layer0_buffer1, 0);
				}
        BufferStatus[0] = BUFFER_FREE;
        current_buffer = next_buffer;
        next_buffer = (current_buffer + 1) % 2;
    }
    else if(BufferStatus[1] == BUFFER_RDY_DISP)
    {
        BufferStatus[1] = BUFFER_BUSY_DISP;
        GenerateDisplayBuffer(1, next_buffer);
        if(next_buffer == 0)
				{
					  __HAL_LTDC_LAYER_ENABLE(&hltdc, 0);
					  __HAL_LTDC_LAYER_DISABLE(&hltdc, 1);
            //HAL_LTDC_SetAddress(&hltdc, (uint32_t) Display_layer0_buffer0, 0);
				}
        else
				{
					  __HAL_LTDC_LAYER_ENABLE(&hltdc, 1);
					  __HAL_LTDC_LAYER_DISABLE(&hltdc, 0);
            //HAL_LTDC_SetAddress(&hltdc, (uint32_t) Display_layer0_buffer1, 0);
				}
        BufferStatus[1] = BUFFER_FREE;
        current_buffer = next_buffer;
        next_buffer = (current_buffer + 1) % 2;
    }
  }
  /* USER CODE END 3 */

}

/** System Clock Configuration
*/
void SystemClock_Config(void)
{

  RCC_OscInitTypeDef RCC_OscInitStruct;
  RCC_ClkInitTypeDef RCC_ClkInitStruct;
  RCC_PeriphCLKInitTypeDef PeriphClkInitStruct;

  __PWR_CLK_ENABLE();

  __HAL_PWR_VOLTAGESCALING_CONFIG(PWR_REGULATOR_VOLTAGE_SCALE1);

  RCC_OscInitStruct.OscillatorType = RCC_OSCILLATORTYPE_HSE;
  RCC_OscInitStruct.HSEState = RCC_HSE_BYPASS;
  RCC_OscInitStruct.PLL.PLLState = RCC_PLL_ON;
  RCC_OscInitStruct.PLL.PLLSource = RCC_PLLSOURCE_HSE;
  RCC_OscInitStruct.PLL.PLLM = 25;
  RCC_OscInitStruct.PLL.PLLN = 400;
  RCC_OscInitStruct.PLL.PLLP = RCC_PLLP_DIV2;
  RCC_OscInitStruct.PLL.PLLQ = 2;
  HAL_RCC_OscConfig(&RCC_OscInitStruct);

  HAL_PWREx_ActivateOverDrive();

  RCC_ClkInitStruct.ClockType = RCC_CLOCKTYPE_HCLK|RCC_CLOCKTYPE_SYSCLK
                              |RCC_CLOCKTYPE_PCLK1|RCC_CLOCKTYPE_PCLK2;
  RCC_ClkInitStruct.SYSCLKSource = RCC_SYSCLKSOURCE_PLLCLK;
  RCC_ClkInitStruct.AHBCLKDivider = RCC_SYSCLK_DIV1;
  RCC_ClkInitStruct.APB1CLKDivider = RCC_HCLK_DIV4;
  RCC_ClkInitStruct.APB2CLKDivider = RCC_HCLK_DIV2;
  HAL_RCC_ClockConfig(&RCC_ClkInitStruct, FLASH_LATENCY_6);

  PeriphClkInitStruct.PeriphClockSelection = RCC_PERIPHCLK_LTDC|RCC_PERIPHCLK_USART1
                              |RCC_PERIPHCLK_I2C1|RCC_PERIPHCLK_I2C3;
  PeriphClkInitStruct.PLLSAI.PLLSAIN = 192;
  PeriphClkInitStruct.PLLSAI.PLLSAIR = 5;
  PeriphClkInitStruct.PLLSAI.PLLSAIQ = 2;
  PeriphClkInitStruct.PLLSAI.PLLSAIP = RCC_PLLP_DIV2;
  PeriphClkInitStruct.PLLSAIDivQ = 1;
  PeriphClkInitStruct.PLLSAIDivR = RCC_PLLSAIDIVR_4;
  PeriphClkInitStruct.Usart1ClockSelection = RCC_USART1CLKSOURCE_PCLK2;
  PeriphClkInitStruct.I2c1ClockSelection = RCC_I2C1CLKSOURCE_PCLK1;
  PeriphClkInitStruct.I2c3ClockSelection = RCC_I2C3CLKSOURCE_PCLK1;
  HAL_RCCEx_PeriphCLKConfig(&PeriphClkInitStruct);

  HAL_RCC_EnableCSS();

  HAL_SYSTICK_Config(HAL_RCC_GetHCLKFreq()/1000);

  HAL_SYSTICK_CLKSourceConfig(SYSTICK_CLKSOURCE_HCLK);

}

/* CRC init function */
void MX_CRC_Init(void)
{

  hcrc.Instance = CRC;
  hcrc.Init.DefaultPolynomialUse = DEFAULT_POLYNOMIAL_ENABLE;
  hcrc.Init.DefaultInitValueUse = DEFAULT_INIT_VALUE_ENABLE;
  hcrc.Init.InputDataInversionMode = CRC_INPUTDATA_INVERSION_NONE;
  hcrc.Init.OutputDataInversionMode = CRC_OUTPUTDATA_INVERSION_DISABLED;
  hcrc.InputDataFormat = CRC_INPUTDATA_FORMAT_HALFWORDS;
  HAL_CRC_Init(&hcrc);

}

/* DMA2D init function */
void MX_DMA2D_Init(void)
{

  hdma2d.Instance = DMA2D;
  hdma2d.Init.Mode = DMA2D_M2M;
  hdma2d.Init.ColorMode = DMA2D_ARGB8888;
  hdma2d.Init.OutputOffset = 0;
  hdma2d.LayerCfg[1].InputOffset = 0;
  hdma2d.LayerCfg[1].InputColorMode = CM_ARGB8888;
  hdma2d.LayerCfg[1].AlphaMode = DMA2D_NO_MODIF_ALPHA;
  hdma2d.LayerCfg[1].InputAlpha = 0xFF;
  HAL_DMA2D_Init(&hdma2d);

  HAL_DMA2D_ConfigLayer(&hdma2d, 1);

}

/* I2C1 init function */
void MX_I2C1_Init(void)
{

  hi2c1.Instance = I2C1;
  hi2c1.Init.Timing = 0x00200A6D;
  hi2c1.Init.OwnAddress1 = 0;
  hi2c1.Init.AddressingMode = I2C_ADDRESSINGMODE_7BIT;
  hi2c1.Init.DualAddressMode = I2C_DUALADDRESS_DISABLE;
  hi2c1.Init.OwnAddress2 = 0;
  hi2c1.Init.OwnAddress2Masks = I2C_OA2_NOMASK;
  hi2c1.Init.GeneralCallMode = I2C_GENERALCALL_DISABLE;
  hi2c1.Init.NoStretchMode = I2C_NOSTRETCH_DISABLE;
  HAL_I2C_Init(&hi2c1);

    /**Configure Analogue filter
    */
  HAL_I2CEx_AnalogFilter_Config(&hi2c1, I2C_ANALOGFILTER_ENABLE);

}

/* I2C3 init function */
void MX_I2C3_Init(void)
{

  hi2c3.Instance = I2C3;
  hi2c3.Init.Timing = 0x00200A6D;
  hi2c3.Init.OwnAddress1 = 0;
  hi2c3.Init.AddressingMode = I2C_ADDRESSINGMODE_7BIT;
  hi2c3.Init.DualAddressMode = I2C_DUALADDRESS_DISABLE;
  hi2c3.Init.OwnAddress2 = 0;
  hi2c3.Init.OwnAddress2Masks = I2C_OA2_NOMASK;
  hi2c3.Init.GeneralCallMode = I2C_GENERALCALL_DISABLE;
  hi2c3.Init.NoStretchMode = I2C_NOSTRETCH_DISABLE;
  HAL_I2C_Init(&hi2c3);

    /**Configure Analogue filter
    */
  HAL_I2CEx_AnalogFilter_Config(&hi2c3, I2C_ANALOGFILTER_ENABLE);

}

/* LTDC init function */
void MX_LTDC_Init(void)
{

  LTDC_LayerCfgTypeDef pLayerCfg;
  LTDC_LayerCfgTypeDef pLayerCfg1;

  hltdc.Instance = LTDC;
  hltdc.Init.HSPolarity = LTDC_HSPOLARITY_AL;
  hltdc.Init.VSPolarity = LTDC_VSPOLARITY_AL;
  hltdc.Init.DEPolarity = LTDC_DEPOLARITY_AL;
  hltdc.Init.PCPolarity = LTDC_PCPOLARITY_IPC;
  hltdc.Init.HorizontalSync = 40;
  hltdc.Init.VerticalSync = 9;
  hltdc.Init.AccumulatedHBP = 53;
  hltdc.Init.AccumulatedVBP = 11;
  hltdc.Init.AccumulatedActiveW = 533;
  hltdc.Init.AccumulatedActiveH = 283;
  hltdc.Init.TotalWidth = 565;
  hltdc.Init.TotalHeigh = 285;
  hltdc.Init.Backcolor.Blue = 0;
  hltdc.Init.Backcolor.Green = 0;
  hltdc.Init.Backcolor.Red = 0;
  HAL_LTDC_Init(&hltdc);

  pLayerCfg.WindowX0 = 0;
  pLayerCfg.WindowX1 = 479;
  pLayerCfg.WindowY0 = 0;
  pLayerCfg.WindowY1 = 271;
  pLayerCfg.PixelFormat = LTDC_PIXEL_FORMAT_ARGB8888;
  pLayerCfg.Alpha = 255;
  pLayerCfg.Alpha0 = 0;
  pLayerCfg.BlendingFactor1 = LTDC_BLENDING_FACTOR1_PAxCA;
  pLayerCfg.BlendingFactor2 = LTDC_BLENDING_FACTOR2_PAxCA;
  pLayerCfg.FBStartAdress = 0xC0000000;
  pLayerCfg.ImageWidth = 480;
  pLayerCfg.ImageHeight = 272;
  pLayerCfg.Backcolor.Blue = 0;
  pLayerCfg.Backcolor.Green = 0;
  pLayerCfg.Backcolor.Red = 0;
  HAL_LTDC_ConfigLayer(&hltdc, &pLayerCfg, 0);

  pLayerCfg1.WindowX0 = 0;
  pLayerCfg1.WindowX1 = 479;
  pLayerCfg1.WindowY0 = 0;
  pLayerCfg1.WindowY1 = 271;
  pLayerCfg1.PixelFormat = LTDC_PIXEL_FORMAT_ARGB8888;
  pLayerCfg1.Alpha = 255;
  pLayerCfg1.Alpha0 = 0;
  pLayerCfg1.BlendingFactor1 = LTDC_BLENDING_FACTOR1_PAxCA;
  pLayerCfg1.BlendingFactor2 = LTDC_BLENDING_FACTOR2_PAxCA;
  pLayerCfg1.FBStartAdress = 0xC0100000;
  pLayerCfg1.ImageWidth = 480;
  pLayerCfg1.ImageHeight = 272;
  pLayerCfg1.Backcolor.Blue = 0;
  pLayerCfg1.Backcolor.Green = 0;
  pLayerCfg1.Backcolor.Red = 0;
  HAL_LTDC_ConfigLayer(&hltdc, &pLayerCfg1, 1);

}

/* SPI2 init function */
void MX_SPI2_Init(void)
{

  hspi2.Instance = SPI2;
  hspi2.Init.Mode = SPI_MODE_MASTER;
  hspi2.Init.Direction = SPI_DIRECTION_2LINES;
  hspi2.Init.DataSize = SPI_DATASIZE_8BIT;
  hspi2.Init.CLKPolarity = SPI_POLARITY_HIGH;
  hspi2.Init.CLKPhase = SPI_PHASE_2EDGE;
  hspi2.Init.NSS = SPI_NSS_SOFT;
  hspi2.Init.BaudRatePrescaler = SPI_BAUDRATEPRESCALER_4;
  hspi2.Init.FirstBit = SPI_FIRSTBIT_MSB;
  hspi2.Init.TIMode = SPI_TIMODE_DISABLED;
  hspi2.Init.CRCCalculation = SPI_CRCCALCULATION_DISABLED;
  hspi2.Init.CRCPolynomial = 10;
  hspi2.Init.CRCLength = SPI_CRC_LENGTH_DATASIZE;
  hspi2.Init.NSSPMode = SPI_NSS_PULSE_DISABLED;
  HAL_SPI_Init(&hspi2);

}

/* TIM2 init function */
void MX_TIM2_Init(void)
{

  TIM_ClockConfigTypeDef sClockSourceConfig;
  TIM_MasterConfigTypeDef sMasterConfig;

  htim2.Instance = TIM2;
  htim2.Init.Prescaler = 99;
  htim2.Init.CounterMode = TIM_COUNTERMODE_DOWN;
  htim2.Init.Period = 0xFFFFFFFF;
  htim2.Init.ClockDivision = TIM_CLOCKDIVISION_DIV1;
  HAL_TIM_Base_Init(&htim2);

  sClockSourceConfig.ClockSource = TIM_CLOCKSOURCE_INTERNAL;
  HAL_TIM_ConfigClockSource(&htim2, &sClockSourceConfig);

  HAL_TIM_OnePulse_Init(&htim2, TIM_OPMODE_SINGLE);

  sMasterConfig.MasterOutputTrigger = TIM_TRGO_RESET;
  sMasterConfig.MasterSlaveMode = TIM_MASTERSLAVEMODE_DISABLE;
  HAL_TIMEx_MasterConfigSynchronization(&htim2, &sMasterConfig);

}

/* USART1 init function */
void MX_USART1_UART_Init(void)
{

  huart1.Instance = USART1;
  huart1.Init.BaudRate = 115200;
  huart1.Init.WordLength = UART_WORDLENGTH_8B;
  huart1.Init.StopBits = UART_STOPBITS_1;
  huart1.Init.Parity = UART_PARITY_NONE;
  huart1.Init.Mode = UART_MODE_TX_RX;
  huart1.Init.HwFlowCtl = UART_HWCONTROL_NONE;
  huart1.Init.OverSampling = UART_OVERSAMPLING_16;
  huart1.Init.OneBitSampling = UART_ONEBIT_SAMPLING_DISABLED;
  huart1.AdvancedInit.AdvFeatureInit = UART_ADVFEATURE_NO_INIT;
  HAL_UART_Init(&huart1);

}

void MX_DMA_Init(void)
{
  /* DMA controller clock enable */
  __HAL_RCC_DMA1_CLK_ENABLE();

  /* DMA interrupt init */
  HAL_NVIC_SetPriority(DMA1_Stream3_IRQn, 4, 0);
  HAL_NVIC_EnableIRQ(DMA1_Stream3_IRQn);
  HAL_NVIC_SetPriority(DMA1_Stream4_IRQn, 3, 0);
  HAL_NVIC_EnableIRQ(DMA1_Stream4_IRQn);

}
/* FMC initialization function */
void MX_FMC_Init(void)
{
  FMC_SDRAM_TimingTypeDef SdramTiming;

  /** Perform the SDRAM1 memory initialization sequence
  */
  hsdram1.Instance = FMC_SDRAM_DEVICE;
  /* hsdram1.Init */
  hsdram1.Init.SDBank = FMC_SDRAM_BANK1;
  hsdram1.Init.ColumnBitsNumber = FMC_SDRAM_COLUMN_BITS_NUM_8;
  hsdram1.Init.RowBitsNumber = FMC_SDRAM_ROW_BITS_NUM_12;
  hsdram1.Init.MemoryDataWidth = FMC_SDRAM_MEM_BUS_WIDTH_16;
  hsdram1.Init.InternalBankNumber = FMC_SDRAM_INTERN_BANKS_NUM_4;
  hsdram1.Init.CASLatency = FMC_SDRAM_CAS_LATENCY_2;
  hsdram1.Init.WriteProtection = FMC_SDRAM_WRITE_PROTECTION_DISABLE;
  hsdram1.Init.SDClockPeriod = FMC_SDRAM_CLOCK_PERIOD_2;
  hsdram1.Init.ReadBurst = FMC_SDRAM_RBURST_ENABLE;
  hsdram1.Init.ReadPipeDelay = FMC_SDRAM_RPIPE_DELAY_0;
  /* SdramTiming */
  SdramTiming.LoadToActiveDelay = 2;
  SdramTiming.ExitSelfRefreshDelay = 6;
  SdramTiming.SelfRefreshTime = 4;
  SdramTiming.RowCycleDelay = 6;
  SdramTiming.WriteRecoveryTime = 2;
  SdramTiming.RPDelay = 2;
  SdramTiming.RCDDelay = 2;

  HAL_SDRAM_Init(&hsdram1, &SdramTiming);

}

/** Configure pins as
        * Analog
        * Input
        * Output
        * EVENT_OUT
        * EXTI
     PE2   ------> QUADSPI_BK1_IO2
     PG14   ------> ETH_TXD1
     PB5   ------> USB_OTG_HS_ULPI_D7
     PB4   ------> S_TIM3_CH1
     PD7   ------> SPDIFRX_IN0
     PC12   ------> SDMMC1_CK
     PE5   ------> DCMI_D6
     PE6   ------> DCMI_D7
     PG13   ------> ETH_TXD0
     PB6   ------> QUADSPI_BK1_NCS
     PG11   ------> ETH_TX_EN
     PC11   ------> SDMMC1_D3
     PC10   ------> SDMMC1_D2
     PA12   ------> USB_OTG_FS_DP
     PI4   ------> SAI2_MCLK_A
     PG10   ------> SAI2_SD_B
     PD3   ------> DCMI_D5
     PA11   ------> USB_OTG_FS_DM
     PI5   ------> SAI2_SCK_A
     PI7   ------> SAI2_FS_A
     PI6   ------> SAI2_SD_A
     PG9   ------> DCMI_VSYNC
     PD2   ------> SDMMC1_CMD
     PA10   ------> USB_OTG_FS_ID
     PH14   ------> DCMI_D4
     PI0   ------> S_TIM5_CH4
     PC9   ------> SDMMC1_D1
     PC8   ------> SDMMC1_D0
     PC7   ------> USART6_RX
     PH4   ------> USB_OTG_HS_ULPI_NXT
     PC6   ------> USART6_TX
     PF7   ------> ADC3_IN5
     PF6   ------> ADC3_IN4
     PB13   ------> USB_OTG_HS_ULPI_D6
     PF10   ------> ADC3_IN8
     PF9   ------> ADC3_IN7
     PF8   ------> ADC3_IN6
     PB12   ------> USB_OTG_HS_ULPI_D5
     PC0   ------> USB_OTG_HS_ULPI_STP
     PC1   ------> ETH_MDC
     PC2   ------> USB_OTG_HS_ULPI_DIR
     PB2   ------> QUADSPI_CLK
     PD12   ------> QUADSPI_BK1_IO1
     PD13   ------> QUADSPI_BK1_IO3
     PH12   ------> DCMI_D3
     PA1   ------> ETH_REF_CLK
     PA0/WKUP   ------> ADCx_IN0
     PA4   ------> DCMI_HSYNC
     PC4   ------> ETH_RXD0
     PD11   ------> QUADSPI_BK1_IO0
     PH9   ------> DCMI_D0
     PH11   ------> DCMI_D2
     PA2   ------> ETH_MDIO
     PA6   ------> DCMI_PIXCLK
     PA5   ------> USB_OTG_HS_ULPI_CK
     PC5   ------> ETH_RXD1
     PB10   ------> USB_OTG_HS_ULPI_D3
     PH6   ------> S_TIM12_CH1
     PH10   ------> DCMI_D1
     PA3   ------> USB_OTG_HS_ULPI_D0
     PA7   ------> ETH_CRS_DV
     PB1   ------> USB_OTG_HS_ULPI_D2
     PB0   ------> USB_OTG_HS_ULPI_D1
     PB11   ------> USB_OTG_HS_ULPI_D4
*/
void MX_GPIO_Init(void)
{

  GPIO_InitTypeDef GPIO_InitStruct;

  /* GPIO Ports Clock Enable */
  __GPIOE_CLK_ENABLE();
  __GPIOG_CLK_ENABLE();
  __GPIOB_CLK_ENABLE();
  __GPIOD_CLK_ENABLE();
  __GPIOC_CLK_ENABLE();
  __GPIOA_CLK_ENABLE();
  __GPIOJ_CLK_ENABLE();
  __GPIOI_CLK_ENABLE();
  __GPIOK_CLK_ENABLE();
  __GPIOF_CLK_ENABLE();
  __GPIOH_CLK_ENABLE();

  /*Configure GPIO pin : PE3 */
  GPIO_InitStruct.Pin = GPIO_PIN_3;
  GPIO_InitStruct.Mode = GPIO_MODE_INPUT;
  GPIO_InitStruct.Pull = GPIO_NOPULL;
  HAL_GPIO_Init(GPIOE, &GPIO_InitStruct);

  /*Configure GPIO pin : PE2 */
  GPIO_InitStruct.Pin = GPIO_PIN_2;
  GPIO_InitStruct.Mode = GPIO_MODE_AF_PP;
  GPIO_InitStruct.Pull = GPIO_NOPULL;
  GPIO_InitStruct.Speed = GPIO_SPEED_HIGH;
  GPIO_InitStruct.Alternate = GPIO_AF9_QUADSPI;
  HAL_GPIO_Init(GPIOE, &GPIO_InitStruct);

  /*Configure GPIO pins : PG14 PG13 PG11 */
  GPIO_InitStruct.Pin = GPIO_PIN_14|GPIO_PIN_13|GPIO_PIN_11;
  GPIO_InitStruct.Mode = GPIO_MODE_AF_PP;
  GPIO_InitStruct.Pull = GPIO_NOPULL;
  GPIO_InitStruct.Speed = GPIO_SPEED_HIGH;
  GPIO_InitStruct.Alternate = GPIO_AF11_ETH;
  HAL_GPIO_Init(GPIOG, &GPIO_InitStruct);

  /*Configure GPIO pins : PB5 PB13 PB12 PB10
                           PB1 PB0 PB11 */
  GPIO_InitStruct.Pin = GPIO_PIN_5|GPIO_PIN_13|GPIO_PIN_12|GPIO_PIN_10
                          |GPIO_PIN_1|GPIO_PIN_0|GPIO_PIN_11;
  GPIO_InitStruct.Mode = GPIO_MODE_AF_PP;
  GPIO_InitStruct.Pull = GPIO_NOPULL;
  GPIO_InitStruct.Speed = GPIO_SPEED_HIGH;
  GPIO_InitStruct.Alternate = GPIO_AF10_OTG_HS;
  HAL_GPIO_Init(GPIOB, &GPIO_InitStruct);

  /*Configure GPIO pin : PB4 */
  GPIO_InitStruct.Pin = GPIO_PIN_4;
  GPIO_InitStruct.Mode = GPIO_MODE_AF_PP;
  GPIO_InitStruct.Pull = GPIO_NOPULL;
  GPIO_InitStruct.Speed = GPIO_SPEED_LOW;
  GPIO_InitStruct.Alternate = GPIO_AF2_TIM3;
  HAL_GPIO_Init(GPIOB, &GPIO_InitStruct);

  /*Configure GPIO pin : PD7 */
  GPIO_InitStruct.Pin = GPIO_PIN_7;
  GPIO_InitStruct.Mode = GPIO_MODE_AF_PP;
  GPIO_InitStruct.Pull = GPIO_NOPULL;
  GPIO_InitStruct.Speed = GPIO_SPEED_LOW;
  GPIO_InitStruct.Alternate = GPIO_AF8_SPDIFRX;
  HAL_GPIO_Init(GPIOD, &GPIO_InitStruct);

  /*Configure GPIO pins : PC12 PC11 PC10 PC9
                           PC8 */
  GPIO_InitStruct.Pin = GPIO_PIN_12|GPIO_PIN_11|GPIO_PIN_10|GPIO_PIN_9
                          |GPIO_PIN_8;
  GPIO_InitStruct.Mode = GPIO_MODE_AF_PP;
  GPIO_InitStruct.Pull = GPIO_NOPULL;
  GPIO_InitStruct.Speed = GPIO_SPEED_HIGH;
  GPIO_InitStruct.Alternate = GPIO_AF12_SDMMC;
  HAL_GPIO_Init(GPIOC, &GPIO_InitStruct);

  /*Configure GPIO pins : PE5 PE6 */
  GPIO_InitStruct.Pin = GPIO_PIN_5|GPIO_PIN_6;
  GPIO_InitStruct.Mode = GPIO_MODE_AF_PP;
  GPIO_InitStruct.Pull = GPIO_NOPULL;
  GPIO_InitStruct.Speed = GPIO_SPEED_LOW;
  GPIO_InitStruct.Alternate = GPIO_AF13_DCMI;
  HAL_GPIO_Init(GPIOE, &GPIO_InitStruct);

  /*Configure GPIO pin : PB6 */
  GPIO_InitStruct.Pin = GPIO_PIN_6;
  GPIO_InitStruct.Mode = GPIO_MODE_AF_PP;
  GPIO_InitStruct.Pull = GPIO_NOPULL;
  GPIO_InitStruct.Speed = GPIO_SPEED_HIGH;
  GPIO_InitStruct.Alternate = GPIO_AF10_QUADSPI;
  HAL_GPIO_Init(GPIOB, &GPIO_InitStruct);

  /*Configure GPIO pin : PJ12 */
  GPIO_InitStruct.Pin = GPIO_PIN_12;
  GPIO_InitStruct.Mode = GPIO_MODE_INPUT;
  GPIO_InitStruct.Pull = GPIO_NOPULL;
  HAL_GPIO_Init(GPIOJ, &GPIO_InitStruct);

  /*Configure GPIO pin : PD6 */
  GPIO_InitStruct.Pin = GPIO_PIN_6;
  GPIO_InitStruct.Mode = GPIO_MODE_EVT_RISING;
  GPIO_InitStruct.Pull = GPIO_NOPULL;
  HAL_GPIO_Init(GPIOD, &GPIO_InitStruct);

  /*Configure GPIO pins : PA12 PA11 PA10 */
  GPIO_InitStruct.Pin = GPIO_PIN_12|GPIO_PIN_11|GPIO_PIN_10;
  GPIO_InitStruct.Mode = GPIO_MODE_AF_PP;
  GPIO_InitStruct.Pull = GPIO_NOPULL;
  GPIO_InitStruct.Speed = GPIO_SPEED_HIGH;
  GPIO_InitStruct.Alternate = GPIO_AF10_OTG_FS;
  HAL_GPIO_Init(GPIOA, &GPIO_InitStruct);

  /*Configure GPIO pins : PI4 PI5 PI7 PI6 */
  GPIO_InitStruct.Pin = GPIO_PIN_4|GPIO_PIN_5|GPIO_PIN_7|GPIO_PIN_6;
  GPIO_InitStruct.Mode = GPIO_MODE_AF_PP;
  GPIO_InitStruct.Pull = GPIO_NOPULL;
  GPIO_InitStruct.Speed = GPIO_SPEED_LOW;
  GPIO_InitStruct.Alternate = GPIO_AF10_SAI2;
  HAL_GPIO_Init(GPIOI, &GPIO_InitStruct);

  /*Configure GPIO pin : PG10 */
  GPIO_InitStruct.Pin = GPIO_PIN_10;
  GPIO_InitStruct.Mode = GPIO_MODE_AF_PP;
  GPIO_InitStruct.Pull = GPIO_NOPULL;
  GPIO_InitStruct.Speed = GPIO_SPEED_LOW;
  GPIO_InitStruct.Alternate = GPIO_AF10_SAI2;
  HAL_GPIO_Init(GPIOG, &GPIO_InitStruct);

  /*Configure GPIO pin : PD5 */
  GPIO_InitStruct.Pin = GPIO_PIN_5;
  GPIO_InitStruct.Mode = GPIO_MODE_OUTPUT_PP;
  GPIO_InitStruct.Pull = GPIO_NOPULL;
  GPIO_InitStruct.Speed = GPIO_SPEED_LOW;
  HAL_GPIO_Init(GPIOD, &GPIO_InitStruct);

  /*Configure GPIO pin : PD3 */
  GPIO_InitStruct.Pin = GPIO_PIN_3;
  GPIO_InitStruct.Mode = GPIO_MODE_AF_PP;
  GPIO_InitStruct.Pull = GPIO_NOPULL;
  GPIO_InitStruct.Speed = GPIO_SPEED_LOW;
  GPIO_InitStruct.Alternate = GPIO_AF13_DCMI;
  HAL_GPIO_Init(GPIOD, &GPIO_InitStruct);

  /*Configure GPIO pins : PI3 PI2 PI12 */
  GPIO_InitStruct.Pin = GPIO_PIN_3|GPIO_PIN_2|GPIO_PIN_12;
  GPIO_InitStruct.Mode = GPIO_MODE_OUTPUT_PP;
  GPIO_InitStruct.Pull = GPIO_NOPULL;
  GPIO_InitStruct.Speed = GPIO_SPEED_LOW;
  HAL_GPIO_Init(GPIOI, &GPIO_InitStruct);

  /*Configure GPIO pin : PC13 */
  GPIO_InitStruct.Pin = GPIO_PIN_13;
  GPIO_InitStruct.Mode = GPIO_MODE_EVT_RISING;
  GPIO_InitStruct.Pull = GPIO_NOPULL;
  HAL_GPIO_Init(GPIOC, &GPIO_InitStruct);

  /*Configure GPIO pin : PK3 */
  GPIO_InitStruct.Pin = GPIO_PIN_3;
  GPIO_InitStruct.Mode = GPIO_MODE_OUTPUT_PP;
  GPIO_InitStruct.Pull = GPIO_NOPULL;
  GPIO_InitStruct.Speed = GPIO_SPEED_HIGH;
  HAL_GPIO_Init(GPIOK, &GPIO_InitStruct);

  /*Configure GPIO pin : PG9 */
  GPIO_InitStruct.Pin = GPIO_PIN_9;
  GPIO_InitStruct.Mode = GPIO_MODE_AF_PP;
  GPIO_InitStruct.Pull = GPIO_NOPULL;
  GPIO_InitStruct.Speed = GPIO_SPEED_LOW;
  GPIO_InitStruct.Alternate = GPIO_AF13_DCMI;
  HAL_GPIO_Init(GPIOG, &GPIO_InitStruct);

  /*Configure GPIO pin : PD4 */
  GPIO_InitStruct.Pin = GPIO_PIN_4;
  GPIO_InitStruct.Mode = GPIO_MODE_INPUT;
  GPIO_InitStruct.Pull = GPIO_NOPULL;
  HAL_GPIO_Init(GPIOD, &GPIO_InitStruct);

  /*Configure GPIO pin : PD2 */
  GPIO_InitStruct.Pin = GPIO_PIN_2;
  GPIO_InitStruct.Mode = GPIO_MODE_AF_PP;
  GPIO_InitStruct.Pull = GPIO_NOPULL;
  GPIO_InitStruct.Speed = GPIO_SPEED_HIGH;
  GPIO_InitStruct.Alternate = GPIO_AF12_SDMMC;
  HAL_GPIO_Init(GPIOD, &GPIO_InitStruct);

  /*Configure GPIO pins : PH15 PH2 */
  GPIO_InitStruct.Pin = GPIO_PIN_15|GPIO_PIN_2;
  GPIO_InitStruct.Mode = GPIO_MODE_INPUT;
  GPIO_InitStruct.Pull = GPIO_NOPULL;
  HAL_GPIO_Init(GPIOH, &GPIO_InitStruct);

  /*Configure GPIO pin : PH13 */
  GPIO_InitStruct.Pin = GPIO_PIN_13;
  GPIO_InitStruct.Mode = GPIO_MODE_OUTPUT_PP;
  GPIO_InitStruct.Pull = GPIO_NOPULL;
  GPIO_InitStruct.Speed = GPIO_SPEED_LOW;
  HAL_GPIO_Init(GPIOH, &GPIO_InitStruct);

  /*Configure GPIO pins : PH14 PH12 PH9 PH11
                           PH10 */
  GPIO_InitStruct.Pin = GPIO_PIN_14|GPIO_PIN_12|GPIO_PIN_9|GPIO_PIN_11
                          |GPIO_PIN_10;
  GPIO_InitStruct.Mode = GPIO_MODE_AF_PP;
  GPIO_InitStruct.Pull = GPIO_NOPULL;
  GPIO_InitStruct.Speed = GPIO_SPEED_LOW;
  GPIO_InitStruct.Alternate = GPIO_AF13_DCMI;
  HAL_GPIO_Init(GPIOH, &GPIO_InitStruct);

  /*Configure GPIO pin : PI0 */
  GPIO_InitStruct.Pin = GPIO_PIN_0;
  GPIO_InitStruct.Mode = GPIO_MODE_AF_PP;
  GPIO_InitStruct.Pull = GPIO_NOPULL;
  GPIO_InitStruct.Speed = GPIO_SPEED_LOW;
  GPIO_InitStruct.Alternate = GPIO_AF2_TIM5;
  HAL_GPIO_Init(GPIOI, &GPIO_InitStruct);

  /*Configure GPIO pin : PI11 */
  GPIO_InitStruct.Pin = GPIO_PIN_11;
  GPIO_InitStruct.Mode = GPIO_MODE_IT_RISING;
  GPIO_InitStruct.Pull = GPIO_NOPULL;
  HAL_GPIO_Init(GPIOI, &GPIO_InitStruct);

  /*Configure GPIO pin : PA8 */
  GPIO_InitStruct.Pin = GPIO_PIN_8;
  GPIO_InitStruct.Mode = GPIO_MODE_OUTPUT_PP;
  GPIO_InitStruct.Pull = GPIO_NOPULL;
  GPIO_InitStruct.Speed = GPIO_SPEED_MEDIUM;
  HAL_GPIO_Init(GPIOA, &GPIO_InitStruct);

  /*Configure GPIO pins : PC7 PC6 */
  GPIO_InitStruct.Pin = GPIO_PIN_7|GPIO_PIN_6;
  GPIO_InitStruct.Mode = GPIO_MODE_AF_PP;
  GPIO_InitStruct.Pull = GPIO_NOPULL;
  GPIO_InitStruct.Speed = GPIO_SPEED_HIGH;
  GPIO_InitStruct.Alternate = GPIO_AF8_USART6;
  HAL_GPIO_Init(GPIOC, &GPIO_InitStruct);

  /*Configure GPIO pin : PH4 */
  GPIO_InitStruct.Pin = GPIO_PIN_4;
  GPIO_InitStruct.Mode = GPIO_MODE_AF_PP;
  GPIO_InitStruct.Pull = GPIO_NOPULL;
  GPIO_InitStruct.Speed = GPIO_SPEED_HIGH;
  GPIO_InitStruct.Alternate = GPIO_AF10_OTG_HS;
  HAL_GPIO_Init(GPIOH, &GPIO_InitStruct);

  /*Configure GPIO pins : PG7 PG6 PG3 */
  GPIO_InitStruct.Pin = GPIO_PIN_7|GPIO_PIN_6|GPIO_PIN_3;
  GPIO_InitStruct.Mode = GPIO_MODE_OUTPUT_PP;
  GPIO_InitStruct.Pull = GPIO_NOPULL;
  GPIO_InitStruct.Speed = GPIO_SPEED_LOW;
  HAL_GPIO_Init(GPIOG, &GPIO_InitStruct);

  /*Configure GPIO pins : PF7 PF6 PF10 PF9
                           PF8 */
  GPIO_InitStruct.Pin = GPIO_PIN_7|GPIO_PIN_6|GPIO_PIN_10|GPIO_PIN_9
                          |GPIO_PIN_8;
  GPIO_InitStruct.Mode = GPIO_MODE_ANALOG;
  GPIO_InitStruct.Pull = GPIO_NOPULL;
  HAL_GPIO_Init(GPIOF, &GPIO_InitStruct);

  /*Configure GPIO pins : PC0 PC2 */
  GPIO_InitStruct.Pin = GPIO_PIN_0|GPIO_PIN_2;
  GPIO_InitStruct.Mode = GPIO_MODE_AF_PP;
  GPIO_InitStruct.Pull = GPIO_NOPULL;
  GPIO_InitStruct.Speed = GPIO_SPEED_HIGH;
  GPIO_InitStruct.Alternate = GPIO_AF10_OTG_HS;
  HAL_GPIO_Init(GPIOC, &GPIO_InitStruct);

  /*Configure GPIO pins : PC1 PC4 PC5 */
  GPIO_InitStruct.Pin = GPIO_PIN_1|GPIO_PIN_4|GPIO_PIN_5;
  GPIO_InitStruct.Mode = GPIO_MODE_AF_PP;
  GPIO_InitStruct.Pull = GPIO_NOPULL;
  GPIO_InitStruct.Speed = GPIO_SPEED_HIGH;
  GPIO_InitStruct.Alternate = GPIO_AF11_ETH;
  HAL_GPIO_Init(GPIOC, &GPIO_InitStruct);

  /*Configure GPIO pin : PB2 */
  GPIO_InitStruct.Pin = GPIO_PIN_2;
  GPIO_InitStruct.Mode = GPIO_MODE_AF_PP;
  GPIO_InitStruct.Pull = GPIO_NOPULL;
  GPIO_InitStruct.Speed = GPIO_SPEED_HIGH;
  GPIO_InitStruct.Alternate = GPIO_AF9_QUADSPI;
  HAL_GPIO_Init(GPIOB, &GPIO_InitStruct);

  /*Configure GPIO pins : PD12 PD13 PD11 */
  GPIO_InitStruct.Pin = GPIO_PIN_12|GPIO_PIN_13|GPIO_PIN_11;
  GPIO_InitStruct.Mode = GPIO_MODE_AF_PP;
  GPIO_InitStruct.Pull = GPIO_NOPULL;
  GPIO_InitStruct.Speed = GPIO_SPEED_HIGH;
  GPIO_InitStruct.Alternate = GPIO_AF9_QUADSPI;
  HAL_GPIO_Init(GPIOD, &GPIO_InitStruct);

  /*Configure GPIO pin : PG2 */
  GPIO_InitStruct.Pin = GPIO_PIN_2;
  GPIO_InitStruct.Mode = GPIO_MODE_INPUT;
  GPIO_InitStruct.Pull = GPIO_NOPULL;
  HAL_GPIO_Init(GPIOG, &GPIO_InitStruct);

  /*Configure GPIO pins : PA1 PA2 PA7 */
  GPIO_InitStruct.Pin = GPIO_PIN_1|GPIO_PIN_2|GPIO_PIN_7;
  GPIO_InitStruct.Mode = GPIO_MODE_AF_PP;
  GPIO_InitStruct.Pull = GPIO_NOPULL;
  GPIO_InitStruct.Speed = GPIO_SPEED_HIGH;
  GPIO_InitStruct.Alternate = GPIO_AF11_ETH;
  HAL_GPIO_Init(GPIOA, &GPIO_InitStruct);

  /*Configure GPIO pin : PA0 */
  GPIO_InitStruct.Pin = GPIO_PIN_0;
  GPIO_InitStruct.Mode = GPIO_MODE_ANALOG;
  GPIO_InitStruct.Pull = GPIO_NOPULL;
  HAL_GPIO_Init(GPIOA, &GPIO_InitStruct);

  /*Configure GPIO pins : PA4 PA6 */
  GPIO_InitStruct.Pin = GPIO_PIN_4|GPIO_PIN_6;
  GPIO_InitStruct.Mode = GPIO_MODE_AF_PP;
  GPIO_InitStruct.Pull = GPIO_NOPULL;
  GPIO_InitStruct.Speed = GPIO_SPEED_LOW;
  GPIO_InitStruct.Alternate = GPIO_AF13_DCMI;
  HAL_GPIO_Init(GPIOA, &GPIO_InitStruct);

  /*Configure GPIO pins : PA5 PA3 */
  GPIO_InitStruct.Pin = GPIO_PIN_5|GPIO_PIN_3;
  GPIO_InitStruct.Mode = GPIO_MODE_AF_PP;
  GPIO_InitStruct.Pull = GPIO_NOPULL;
  GPIO_InitStruct.Speed = GPIO_SPEED_HIGH;
  GPIO_InitStruct.Alternate = GPIO_AF10_OTG_HS;
  HAL_GPIO_Init(GPIOA, &GPIO_InitStruct);

  /*Configure GPIO pin : PH6 */
  GPIO_InitStruct.Pin = GPIO_PIN_6;
  GPIO_InitStruct.Mode = GPIO_MODE_AF_PP;
  GPIO_InitStruct.Pull = GPIO_NOPULL;
  GPIO_InitStruct.Speed = GPIO_SPEED_LOW;
  GPIO_InitStruct.Alternate = GPIO_AF9_TIM12;
  HAL_GPIO_Init(GPIOH, &GPIO_InitStruct);

  /* EXTI interrupt init*/
  HAL_NVIC_SetPriority(EXTI15_10_IRQn, 1, 0);
  HAL_NVIC_EnableIRQ(EXTI15_10_IRQn);

}

/* USER CODE BEGIN 4 */
static void SDRAM_Init()
{
  __IO uint32_t tmpmrd =0;
  /* Step 3:  Configure a clock configuration enable command */
  command.CommandMode = FMC_SDRAM_CMD_CLK_ENABLE;
  command.CommandTarget = FMC_SDRAM_CMD_TARGET_BANK1;
  command.AutoRefreshNumber = 1;
  command.ModeRegisterDefinition = 0;

  /* Send the command */
  HAL_SDRAM_SendCommand(&hsdram1, &command, SDRAM_TIMEOUT);

  /* Step 4: Insert 100 us minimum delay */
  /* Inserted delay is equal to 1 ms due to systick time base unit (ms) */
  HAL_Delay(1);

  /* Step 5: Configure a PALL (precharge all) command */
  command.CommandMode = FMC_SDRAM_CMD_PALL;
  command.CommandTarget = FMC_SDRAM_CMD_TARGET_BANK1;
  command.AutoRefreshNumber = 1;
  command.ModeRegisterDefinition = 0;

  /* Send the command */
  HAL_SDRAM_SendCommand(&hsdram1, &command, SDRAM_TIMEOUT);

  /* Step 6 : Configure a Auto-Refresh command */
  command.CommandMode = FMC_SDRAM_CMD_AUTOREFRESH_MODE;
  command.CommandTarget = FMC_SDRAM_CMD_TARGET_BANK1;
  command.AutoRefreshNumber = 8;
  command.ModeRegisterDefinition = 0;

  /* Send the command */
  HAL_SDRAM_SendCommand(&hsdram1, &command, SDRAM_TIMEOUT);

  /* Step 7: Program the external memory mode register */
  tmpmrd = (uint32_t)SDRAM_MODEREG_BURST_LENGTH_1          |
                     SDRAM_MODEREG_BURST_TYPE_SEQUENTIAL   |
                     SDRAM_MODEREG_CAS_LATENCY_2           |
                     SDRAM_MODEREG_OPERATING_MODE_STANDARD |
                     SDRAM_MODEREG_WRITEBURST_MODE_SINGLE;

  command.CommandMode = FMC_SDRAM_CMD_LOAD_MODE;
  command.CommandTarget = FMC_SDRAM_CMD_TARGET_BANK1;
  command.AutoRefreshNumber = 1;
  command.ModeRegisterDefinition = tmpmrd;

  /* Send the command */
  HAL_SDRAM_SendCommand(&hsdram1, &command, SDRAM_TIMEOUT);

  /* Step 8: Set the refresh rate counter */
  /* (15.62 us x Freq) - 20 */
  /* Set the device refresh counter */
  hsdram1.Instance->SDRTR |= ((uint32_t)((1292)<< 1));

}

void ArrayMaxMin(uint16_t * LeptonBuffer, uint16_t * min, uint16_t * max)
{
    unsigned int i;
    *min = *LeptonBuffer;
    *max = *LeptonBuffer;
    LeptonBuffer++;
    for(i = 1; i < 60*80; i++)
    {
        if(*LeptonBuffer < *min)
            *min = *LeptonBuffer;
        if(*LeptonBuffer > *max)
            *max = *LeptonBuffer;
        LeptonBuffer++;
    }
}

/*
Display the thermal image with an offset of (80,16) and a size of (320,240)
Display is 480x272
*/
void GenerateDisplayBuffer(uint8_t LeptonBufferID, uint8_t DisplayBufferID)
{
    int x, y;
    uint16_t l_min, l_max;
    float range;
    uint32_t color;
    uint32_t * DisplayBuffer = (DisplayBufferID == 0)?Display_layer0:Display_layer1;
    ArrayMaxMin(LeptonBuffer[LeptonBufferID], &l_min, &l_max);
    range = l_max-l_min;
    for(y = 0; y < 60; y++)
    {
        for(x = 0; x < 80; x++)
        {
            color = gradient(((float)(LeptonBuffer[LeptonBufferID][y*80+x]-l_min))/range);
            DisplayBuffer[((y*4)+16)*480 + (x*4)+80] = color;
            DisplayBuffer[((y*4)+16)*480 + (x*4)+81] = color;
            DisplayBuffer[((y*4)+16)*480 + (x*4)+82] = color;
            DisplayBuffer[((y*4)+16)*480 + (x*4)+83] = color;

            DisplayBuffer[((y*4)+17)*480 + (x*4)+80] = color;
            DisplayBuffer[((y*4)+17)*480 + (x*4)+81] = color;
            DisplayBuffer[((y*4)+17)*480 + (x*4)+82] = color;
            DisplayBuffer[((y*4)+17)*480 + (x*4)+83] = color;

            DisplayBuffer[((y*4)+18)*480 + (x*4)+80] = color;
            DisplayBuffer[((y*4)+18)*480 + (x*4)+81] = color;
            DisplayBuffer[((y*4)+18)*480 + (x*4)+82] = color;
            DisplayBuffer[((y*4)+18)*480 + (x*4)+83] = color;

            DisplayBuffer[((y*4)+19)*480 + (x*4)+80] = color;
            DisplayBuffer[((y*4)+19)*480 + (x*4)+81] = color;
            DisplayBuffer[((y*4)+19)*480 + (x*4)+82] = color;
            DisplayBuffer[((y*4)+19)*480 + (x*4)+83] = color;
        }
    }
}

uint32_t gradient(float percent)
{
    if(percent < 0.0f)
        percent = 0.0f;
    if(percent > 1.0f)
        percent = 1.0f;
    if(percent < 0.5f)
    {
        if(percent < 0.25f)
        {
            //Black to blue
            return two_colors_gradient(percent * 4, 0, 0, 0, 0, 0, 255);
        }
        else
        {
            //Blue to yellow
            if(percent < 0.375f)
                return two_colors_gradient((percent - 0.25f) * 8, 0, 0, 255, 0, 255, 0);
            else
                return two_colors_gradient((percent - 0.375f) * 8, 0, 255, 0, 255, 255, 0);
        }
    }
    else
    {
        if(percent < 0.75f)
        {
            //Yellow to red
            return two_colors_gradient((percent * 4) - 2, 255, 255, 0, 255, 0, 0);
        }
        else
        {
            //Red to white
            return two_colors_gradient((percent * 4) - 3, 255, 0, 0, 255, 255, 255);
        }
    }
}

uint32_t two_colors_gradient(float percent, uint8_t r_1, uint8_t g_1, uint8_t b_1, uint8_t r_2, uint8_t g_2, uint8_t b_2)
{
    float weigthed_percent = (cos(((double)percent - 1.0) * PI) + 1.0f) / 2.0f;
    return RGB(255,
        (uint8_t)(MIN(r_1, r_2) + ABS((float)((int32_t)r_1 - (int32_t)r_2)) * (r_1 > r_2 ? 1.0f-weigthed_percent : weigthed_percent)),
        (uint8_t)(MIN(g_1, g_2) + ABS((float)((int32_t)g_1 - (int32_t)g_2)) * (g_1 > g_2 ? 1.0f-weigthed_percent : weigthed_percent)),
        (uint8_t)(MIN(b_1, b_2) + ABS((float)((int32_t)b_1 - (int32_t)b_2)) * (b_1 > b_2 ? 1.0f-weigthed_percent : weigthed_percent)));
}

//void drawButton(int x, int y)
//{
//    while(DMA2D->CR & 0x00000001);
//    DMA2D->FGMAR = (uint32_t) Button_Layout;
//    DMA2D->FGOR = 0;
//    DMA2D->FGPFCCR = 0xFF000000;
//    DMA2D->OPFCCR = 0x00000000;
//    DMA2D->OMAR = ((uint32_t) Display_layer1) + (y * 480 + x) * 4;
//    DMA2D->OOR = 480-64;
//    DMA2D->NLR = 64 << 16 | 32;
//    DMA2D->CR |= 1;
//}
/* USER CODE END 4 */

/************************ (C) COPYRIGHT STMicroelectronics *****END OF FILE****/
